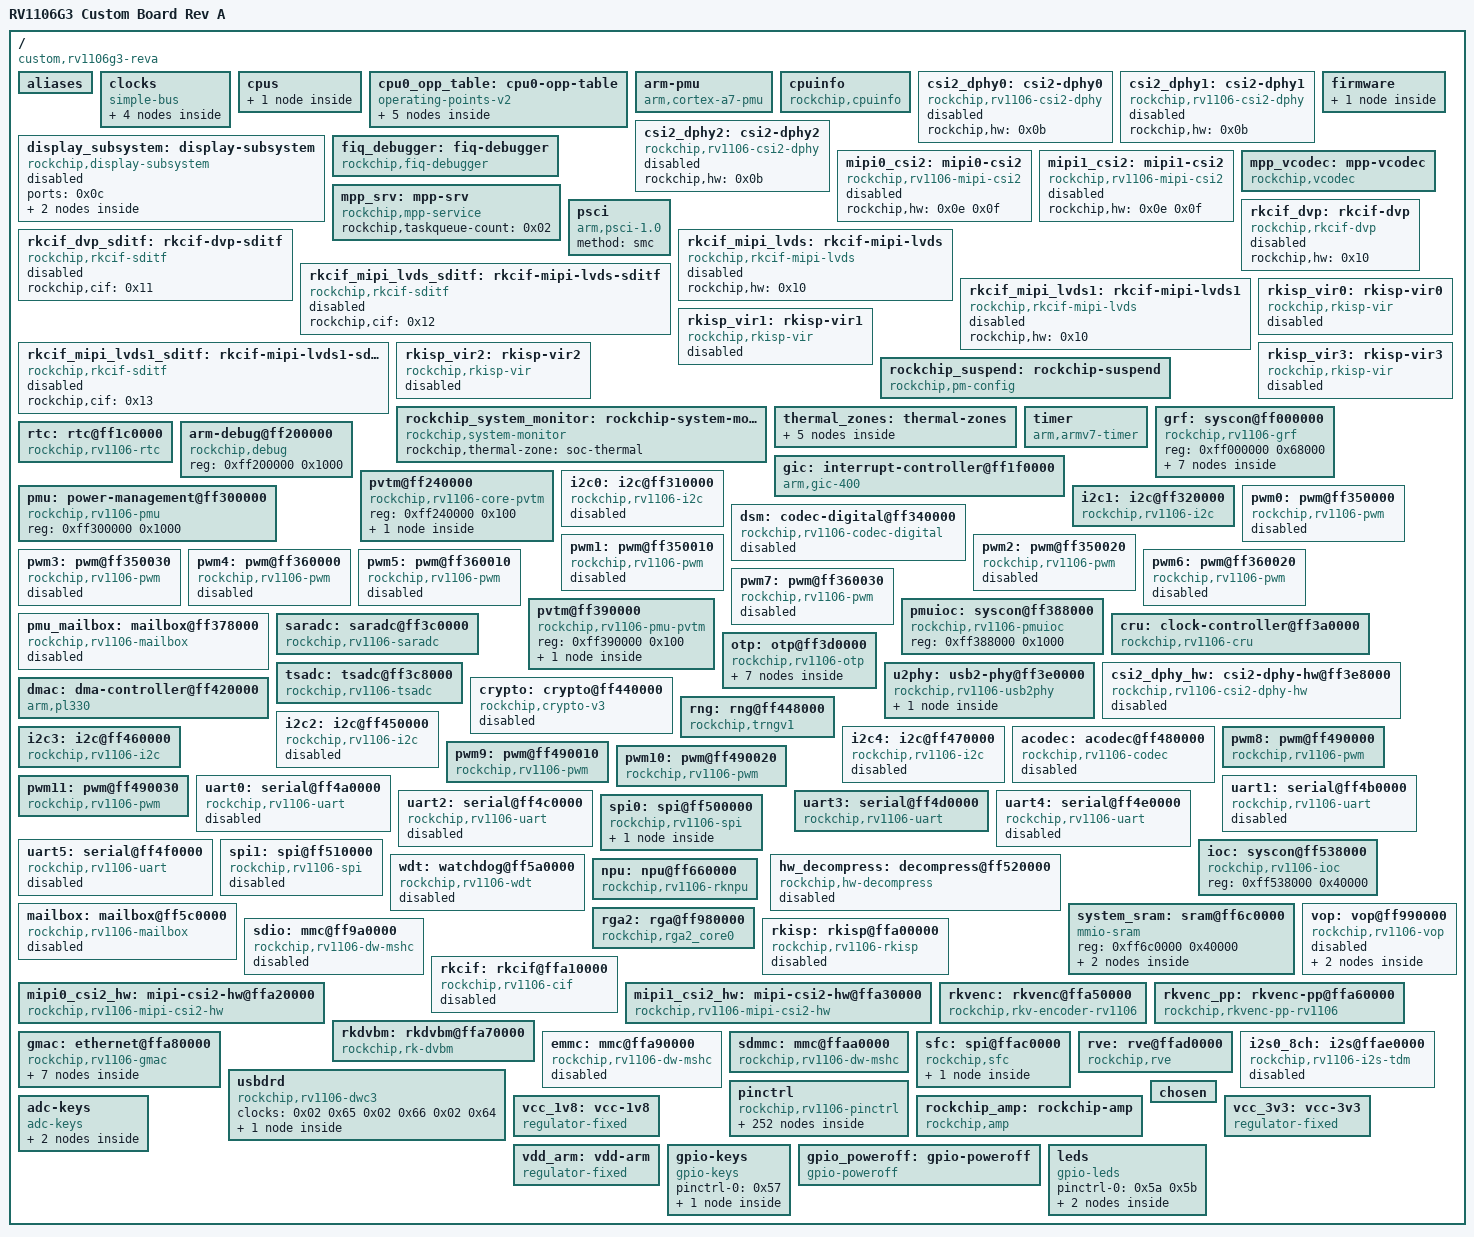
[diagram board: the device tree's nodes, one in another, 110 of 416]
/dts-v1/;

/ {
	#address-cells = <0x01>;
	#size-cells = <0x01>;
	compatible = "custom,rv1106g3-reva", "rockchip,rv1103g-38x38-ipc-v10", "rockchip,rv1106g3";
	interrupt-parent = <0x01>;
	model = "RV1106G3 Custom Board Rev A";

	aliases {
		csi2dphy0 = "/csi2-dphy0";
		csi2dphy1 = "/csi2-dphy1";
		csi2dphy2 = "/csi2-dphy2";
		ethernet0 = "/ethernet@ffa80000";
		gpio0 = "/pinctrl/gpio@ff380000";
		gpio1 = "/pinctrl/gpio@ff530000";
		gpio2 = "/pinctrl/gpio@ff540000";
		gpio3 = "/pinctrl/gpio@ff550000";
		gpio4 = "/pinctrl/gpio@ff560000";
		i2c0 = "/i2c@ff310000";
		i2c1 = "/i2c@ff320000";
		i2c2 = "/i2c@ff450000";
		i2c3 = "/i2c@ff460000";
		i2c4 = "/i2c@ff470000";
		mmc0 = "/mmc@ffa90000";
		mmc1 = "/mmc@ffaa0000";
		mmc2 = "/mmc@ff9a0000";
		pwm0 = "/pwm@ff350000";
		pwm1 = "/pwm@ff350010";
		pwm2 = "/pwm@ff350020";
		pwm3 = "/pwm@ff350030";
		pwm4 = "/pwm@ff360000";
		pwm5 = "/pwm@ff360010";
		pwm6 = "/pwm@ff360020";
		pwm7 = "/pwm@ff360030";
		pwm8 = "/pwm@ff490000";
		pwm9 = "/pwm@ff490010";
		pwm10 = "/pwm@ff490020";
		pwm11 = "/pwm@ff490030";
		rkcif_mipi_lvds0 = "/rkcif-mipi-lvds";
		rkcif_mipi_lvds1 = "/rkcif-mipi-lvds1";
		serial0 = "/serial@ff4a0000";
		serial1 = "/serial@ff4b0000";
		serial2 = "/serial@ff4c0000";
		serial3 = "/serial@ff4d0000";
		serial4 = "/serial@ff4e0000";
		serial5 = "/serial@ff4f0000";
		spi0 = "/spi@ff500000";
		spi1 = "/spi@ff510000";
		spi2 = "/spi@ffac0000";
	};

	clocks {
		compatible = "simple-bus";

		cpu_pvtpll: cpu-pvtpll {
			compatible = "fixed-clock";
			clock-frequency = "M|m";
			clock-output-names = "cpu_pvtpll";
			#clock-cells = <0x00>;
			status = "disabled";
			phandle = <0x5d>;
		};

		rkvenc_pvtpll: pvtpll-0 {
			compatible = "fixed-clock";
			clock-frequency = <0x18701a80>;
			clock-output-names = "clk_pvtpll_0";
			#clock-cells = <0x00>;
			phandle = <0x5e>;
		};

		npu_pvtpll: pvtpll-1 {
			compatible = "fixed-clock";
			clock-frequency = <0x1908b100>;
			clock-output-names = "clk_pvtpll_1";
			#clock-cells = <0x00>;
			phandle = <0x5f>;
		};

		xin24m: oscillator {
			compatible = "fixed-clock";
			clock-frequency = <0x16e3600>;
			clock-output-names = "xin24m";
			#clock-cells = <0x00>;
			phandle = <0x60>;
		};
	};

	cpus {
		#address-cells = <0x01>;
		#size-cells = <0x00>;

		cpu0: cpu@0 {
			device_type = "cpu";
			compatible = "arm,cortex-a7";
			reg = <0x00>;
			clocks = <0x02 0x05>;
			operating-points-v2 = <0x03>;
			cpu-supply = <0x04>;
			phandle = <0x07>;
		};
	};

	cpu0_opp_table: cpu0-opp-table {
		compatible = "operating-points-v2";
		opp-shared;
		nvmem-cells = <0x05>;
		nvmem-cell-names = "leakage";
		rockchip,pvtpll-avg-offset = <0x4001c>;
		rockchip,pvtpll-min-rate = <0x10d880>;
		rockchip,pvtpll-volt-step = <0x30d4>;
		rockchip,grf = <0x06>;
		rockchip,temp-hysteresis = <0x1388>;
		rockchip,low-temp = <0x2710>;
		rockchip,low-temp-min-volt = <0xdbba0>;
		phandle = <0x03>;

		opp-408000000 {
			opp-hz = <0x00 0x18519600>;
			opp-microvolt = <0xcf850 0xcf850 0xf4240>;
			clock-latency-ns = <0x9c40>;
		};

		opp-600000000 {
			opp-hz = <0x00 0x23c34600>;
			opp-microvolt = <0xcf850 0xcf850 0xf4240>;
			clock-latency-ns = <0x9c40>;
		};

		opp-816000000 {
			opp-hz = <0x00 0x30a32c00>;
			opp-microvolt = <0xcf850 0xcf850 0xf4240>;
			clock-latency-ns = <0x9c40>;
			opp-suspend;
		};

		opp-1104000000 {
			opp-hz = <0x00 0x41cdb400>;
			opp-microvolt = <0xcf850 0xcf850 0xf4240>;
			clock-latency-ns = <0x9c40>;
		};

		opp-1200000000 {
			opp-hz = <0x00 0x47868c00>;
			opp-microvolt = <0xcf850 0xcf850 0xf4240>;
			clock-latency-ns = <0x9c40>;
		};
	};

	arm-pmu {
		compatible = "arm,cortex-a7-pmu";
		interrupts = <0x00 0x7e 0x04>;
		interrupt-affinity = <0x07>;
	};

	cpuinfo {
		compatible = "rockchip,cpuinfo";
		nvmem-cells = <0x08 0x09 0x0a>;
		nvmem-cell-names = "id", "cpu-version", "cpu-code";
	};

	csi2_dphy0: csi2-dphy0 {
		compatible = "rockchip,rv1106-csi2-dphy";
		rockchip,hw = <0x0b>;
		status = "disabled";
		phandle = <0x61>;
	};

	csi2_dphy1: csi2-dphy1 {
		compatible = "rockchip,rv1106-csi2-dphy";
		rockchip,hw = <0x0b>;
		status = "disabled";
		phandle = <0x62>;
	};

	csi2_dphy2: csi2-dphy2 {
		compatible = "rockchip,rv1106-csi2-dphy";
		rockchip,hw = <0x0b>;
		status = "disabled";
		phandle = <0x63>;
	};

	display_subsystem: display-subsystem {
		compatible = "rockchip,display-subsystem";
		ports = <0x0c>;
		status = "disabled";
		phandle = <0x64>;

		route {

			route_rgb: route-rgb {
				status = "disabled";
				logo,uboot = "logo.bmp";
				logo,kernel = "logo_kernel.bmp";
				logo,mode = "center";
				charge_logo,mode = "center";
				connect = <0x0d>;
				phandle = <0x65>;
			};
		};
	};

	fiq_debugger: fiq-debugger {
		compatible = "rockchip,fiq-debugger";
		rockchip,serial-id = <0x02>;
		rockchip,wake-irq = <0x00>;
		rockchip,irq-mode-enable = <0x01>;
		rockchip,baudrate = <0x1c200>;
		interrupts = <0x00 0x7d 0x04>;
		status = "okay";
		phandle = <0x66>;
	};

	firmware {

		optee: optee {
			compatible = "linaro,optee-tz";
			method = "smc";
			status = "disabled";
			phandle = <0x67>;
		};
	};

	mipi0_csi2: mipi0-csi2 {
		compatible = "rockchip,rv1106-mipi-csi2";
		rockchip,hw = <0x0e 0x0f>;
		status = "disabled";
		phandle = <0x68>;
	};

	mipi1_csi2: mipi1-csi2 {
		compatible = "rockchip,rv1106-mipi-csi2";
		rockchip,hw = <0x0e 0x0f>;
		status = "disabled";
		phandle = <0x69>;
	};

	mpp_srv: mpp-srv {
		compatible = "rockchip,mpp-service";
		rockchip,taskqueue-count = <0x02>;
		status = "okay";
		phandle = <0x3d>;
	};

	mpp_vcodec: mpp-vcodec {
		compatible = "rockchip,vcodec";
		status = "okay";
		phandle = <0x6a>;
	};

	psci {
		compatible = "arm,psci-1.0";
		method = "smc";
	};

	rkcif_dvp: rkcif-dvp {
		compatible = "rockchip,rkcif-dvp";
		rockchip,hw = <0x10>;
		status = "disabled";
		phandle = <0x11>;
	};

	rkcif_dvp_sditf: rkcif-dvp-sditf {
		compatible = "rockchip,rkcif-sditf";
		rockchip,cif = <0x11>;
		status = "disabled";
		phandle = <0x6b>;
	};

	rkcif_mipi_lvds: rkcif-mipi-lvds {
		compatible = "rockchip,rkcif-mipi-lvds";
		rockchip,hw = <0x10>;
		status = "disabled";
		phandle = <0x12>;
	};

	rkcif_mipi_lvds_sditf: rkcif-mipi-lvds-sditf {
		compatible = "rockchip,rkcif-sditf";
		rockchip,cif = <0x12>;
		status = "disabled";
		phandle = <0x6c>;
	};

	rkcif_mipi_lvds1: rkcif-mipi-lvds1 {
		compatible = "rockchip,rkcif-mipi-lvds";
		rockchip,hw = <0x10>;
		status = "disabled";
		phandle = <0x13>;
	};

	rkcif_mipi_lvds1_sditf: rkcif-mipi-lvds1-sditf {
		compatible = "rockchip,rkcif-sditf";
		rockchip,cif = <0x13>;
		status = "disabled";
		phandle = <0x6d>;
	};

	rkisp_vir0: rkisp-vir0 {
		compatible = "rockchip,rkisp-vir";
		rockchip,hw = <0x14>;
		dvbm = <0x15>;
		status = "disabled";
		phandle = <0x6e>;
	};

	rkisp_vir1: rkisp-vir1 {
		compatible = "rockchip,rkisp-vir";
		rockchip,hw = <0x14>;
		dvbm = <0x15>;
		status = "disabled";
		phandle = <0x6f>;
	};

	rkisp_vir2: rkisp-vir2 {
		compatible = "rockchip,rkisp-vir";
		rockchip,hw = <0x14>;
		dvbm = <0x15>;
		status = "disabled";
		phandle = <0x70>;
	};

	rkisp_vir3: rkisp-vir3 {
		compatible = "rockchip,rkisp-vir";
		rockchip,hw = <0x14>;
		dvbm = <0x15>;
		status = "disabled";
		phandle = <0x71>;
	};

	rockchip_suspend: rockchip-suspend {
		compatible = "rockchip,pm-config";
		status = "okay";
		rockchip,sleep-io-config = <0x800 0x10800 0x20800 0x30400 0x40400 0x50000 0x60000>;
		phandle = <0x72>;
	};

	rockchip_system_monitor: rockchip-system-monitor {
		compatible = "rockchip,system-monitor";
		rockchip,thermal-zone = "soc-thermal";
		phandle = <0x73>;
	};

	thermal_zones: thermal-zones {
		phandle = <0x74>;

		soc_thermal: soc-thermal {
			polling-delay-passive = <0x14>;
			polling-delay = <0x3e8>;
			sustainable-power = <0x834>;
			thermal-sensors = <0x16 0x00>;
			phandle = <0x75>;

			trips {

				threshold: trip-point-0 {
					temperature = <0x124f8>;
					hysteresis = <0x7d0>;
					type = "passive";
					phandle = <0x76>;
				};

				target: trip-point-1 {
					temperature = <0x14c08>;
					hysteresis = <0x7d0>;
					type = "passive";
					phandle = <0x77>;
				};

				soc_crit: soc-crit {
					temperature = <0x1c138>;
					hysteresis = <0x7d0>;
					type = "critical";
					phandle = <0x78>;
				};
			};
		};
	};

	timer {
		compatible = "arm,armv7-timer";
		interrupts = <0x01 0x0d 0x104 0x01 0x0e 0x104>;
		clock-frequency = <0x16e3600>;
	};

	grf: syscon@ff000000 {
		compatible = "rockchip,rv1106-grf", "syscon", "simple-mfd";
		reg = <0xff000000 0x68000>;
		phandle = <0x06>;

		grf_cru: grf-clock-controller {
			compatible = "rockchip,rv1106-grf-cru";
			#clock-cells = <0x01>;
			phandle = <0x3b>;
		};

		reboot_mode: reboot-mode {
			compatible = "syscon-reboot-mode";
			offset = <0x20200>;
			mode-bootloader = <0x5242c301>;
			mode-charge = <0x5242c30b>;
			mode-fastboot = <0x5242c309>;
			mode-loader = <0x5242c301>;
			mode-normal = <0x5242c300>;
			mode-recovery = <0x5242c303>;
			mode-ums = <0x5242c30c>;
			mode-panic = <0x5242c307>;
			mode-watchdog = <0x5242c308>;
			phandle = <0x79>;
		};

		rgb: rgb {
			compatible = "rockchip,rv1106-rgb";
			status = "disabled";
			phandle = <0x7a>;

			ports {
				#address-cells = <0x01>;
				#size-cells = <0x00>;

				port@0 {
					reg = <0x00>;
					#address-cells = <0x01>;
					#size-cells = <0x00>;

					rgb_in_vop: endpoint@0 {
						reg = <0x00>;
						remote-endpoint = <0x0d>;
						phandle = <0x3a>;
					};
				};
			};
		};

		rknpor_powergood: rknpor-powergood {
			compatible = "rockchip,rv1106-npor-powergood";
			interrupts = <0x00 0x56 0x04>;
			status = "okay";
			phandle = <0x7b>;
		};
	};

	rtc: rtc@ff1c0000 {
		compatible = "rockchip,rv1106-rtc";
		reg = <0xff1c0000 0x1000>;
		rockchip,grf = <0x06>;
		interrupts = <0x00 0x62 0x04>;
		clocks = <0x02 0xef 0x02 0xee>;
		clock-names = "pclk_phy", "pclk_test";
		assigned-clocks = <0x02 0xef>;
		assigned-clock-rates = <0x16e3600>;
		status = "okay";
		phandle = <0x7c>;
	};

	gic: interrupt-controller@ff1f0000 {
		compatible = "arm,gic-400";
		interrupt-controller;
		#interrupt-cells = <0x03>;
		#address-cells = <0x00>;
		reg = <0xff1f1000 0x1000 0xff1f2000 0x2000 0xff1f4000 0x2000 0xff1f6000 0x2000>;
		interrupts = <0x01 0x09 0x104>;
		phandle = <0x01>;
	};

	arm-debug@ff200000 {
		compatible = "rockchip,debug";
		reg = <0xff200000 0x1000>;
	};

	pvtm@ff240000 {
		compatible = "rockchip,rv1106-core-pvtm";
		reg = <0xff240000 0x100>;
		#address-cells = <0x01>;
		#size-cells = <0x00>;

		pvtm@0 {
			reg = <0x00>;
			clocks = <0x02 0x40>;
			clock-names = "clk";
			resets = <0x02 0x6000e 0x02 0x6000f>;
			reset-names = "rst", "rst-p";
		};
	};

	pmu: power-management@ff300000 {
		compatible = "rockchip,rv1106-pmu", "syscon";
		reg = <0xff300000 0x1000>;
		phandle = <0x7d>;
	};

	i2c0: i2c@ff310000 {
		compatible = "rockchip,rv1106-i2c", "rockchip,rk3399-i2c";
		reg = <0xff310000 0x1000>;
		interrupts = <0x00 0x12 0x04>;
		#address-cells = <0x01>;
		#size-cells = <0x00>;
		clocks = <0x02 0x2a 0x02 0x29>;
		clock-names = "i2c", "pclk";
		pinctrl-names = "default";
		pinctrl-0 = <0x17>;
		status = "disabled";
		phandle = <0x7e>;
	};

	i2c1: i2c@ff320000 {
		compatible = "rockchip,rv1106-i2c", "rockchip,rk3399-i2c";
		reg = <0xff320000 0x1000>;
		interrupts = <0x00 0x13 0x04>;
		#address-cells = <0x01>;
		#size-cells = <0x00>;
		clocks = <0x02 0x78 0x02 0x77>;
		clock-names = "i2c", "pclk";
		pinctrl-names = "default";
		pinctrl-0 = <0x18>;
		status = "okay";
		clock-frequency = <0x186a0>;
		phandle = <0x7f>;
	};

	dsm: codec-digital@ff340000 {
		compatible = "rockchip,rv1106-codec-digital", "rockchip,codec-digital-v1";
		reg = <0xff340000 0x1000>;
		clocks = <0x02 0x24 0x02 0x23>;
		clock-names = "dac", "pclk";
		resets = <0x02 0x48061>;
		reset-names = "reset";
		rockchip,grf = <0x06>;
		rockchip,pwm-output-mode;
		#sound-dai-cells = <0x00>;
		pinctrl-names = "default";
		pinctrl-0 = <0x19>;
		status = "disabled";
		phandle = <0x80>;
	};

	pwm0: pwm@ff350000 {
		compatible = "rockchip,rv1106-pwm", "rockchip,rk3328-pwm";
		reg = <0xff350000 0x10>;
		interrupts = <0x00 0x1f 0x04>;
		#pwm-cells = <0x03>;
		pinctrl-names = "active";
		pinctrl-0 = <0x1a>;
		clocks = <0x02 0x36 0x02 0x35>;
		clock-names = "pwm", "pclk";
		status = "disabled";
		phandle = <0x81>;
	};

	pwm1: pwm@ff350010 {
		compatible = "rockchip,rv1106-pwm", "rockchip,rk3328-pwm";
		reg = <0xff350010 0x10>;
		interrupts = <0x00 0x1f 0x04>;
		#pwm-cells = <0x03>;
		pinctrl-names = "active";
		pinctrl-0 = <0x1b>;
		clocks = <0x02 0x36 0x02 0x35>;
		clock-names = "pwm", "pclk";
		status = "disabled";
		phandle = <0x82>;
	};

	pwm2: pwm@ff350020 {
		compatible = "rockchip,rv1106-pwm", "rockchip,rk3328-pwm";
		reg = <0xff350020 0x10>;
		interrupts = <0x00 0x1f 0x04>;
		#pwm-cells = <0x03>;
		pinctrl-names = "active";
		pinctrl-0 = <0x1c>;
		clocks = <0x02 0x36 0x02 0x35>;
		clock-names = "pwm", "pclk";
		status = "disabled";
		phandle = <0x83>;
	};

	pwm3: pwm@ff350030 {
		compatible = "rockchip,rv1106-pwm", "rockchip,rk3328-pwm";
		reg = <0xff350030 0x10>;
		interrupts = <0x00 0x1f 0x04 0x00 0x20 0x04>;
		#pwm-cells = <0x03>;
		pinctrl-names = "active";
		pinctrl-0 = <0x1d>;
		clocks = <0x02 0x36 0x02 0x35>;
		clock-names = "pwm", "pclk";
		status = "disabled";
		phandle = <0x84>;
	};

	pwm4: pwm@ff360000 {
		compatible = "rockchip,rv1106-pwm", "rockchip,rk3328-pwm";
		reg = <0xff360000 0x10>;
		interrupts = <0x00 0x21 0x04>;
		#pwm-cells = <0x03>;
		pinctrl-names = "active";
		pinctrl-0 = <0x1e>;
		clocks = <0x02 0x44 0x02 0x43>;
		clock-names = "pwm", "pclk";
		status = "disabled";
		phandle = <0x85>;
	};

	pwm5: pwm@ff360010 {
		compatible = "rockchip,rv1106-pwm", "rockchip,rk3328-pwm";
		reg = <0xff360010 0x10>;
		interrupts = <0x00 0x21 0x04>;
		#pwm-cells = <0x03>;
		pinctrl-names = "active";
		pinctrl-0 = <0x1f>;
		clocks = <0x02 0x44 0x02 0x43>;
		clock-names = "pwm", "pclk";
		status = "disabled";
		phandle = <0x86>;
	};

	pwm6: pwm@ff360020 {
		compatible = "rockchip,rv1106-pwm", "rockchip,rk3328-pwm";
		reg = <0xff360020 0x10>;
		interrupts = <0x00 0x21 0x04>;
		#pwm-cells = <0x03>;
		pinctrl-names = "active";
		pinctrl-0 = <0x20>;
		clocks = <0x02 0x44 0x02 0x43>;
		clock-names = "pwm", "pclk";
		status = "disabled";
		phandle = <0x87>;
	};

	pwm7: pwm@ff360030 {
		compatible = "rockchip,rv1106-pwm", "rockchip,rk3328-pwm";
		reg = <0xff360030 0x10>;
		interrupts = <0x00 0x21 0x04 0x00 0x22 0x04>;
		#pwm-cells = <0x03>;
		pinctrl-names = "active";
		pinctrl-0 = <0x21>;
		clocks = <0x02 0x44 0x02 0x43>;
		clock-names = "pwm", "pclk";
		status = "disabled";
		phandle = <0x88>;
	};

	pmu_mailbox: mailbox@ff378000 {
		compatible = "rockchip,rv1106-mailbox", "rockchip,rk3368-mailbox";
		reg = <0xff378000 0x200>;
		interrupts = <0x00 0x72 0x04>;
		clocks = <0x02 0x7a>;
		clock-names = "pclk_mailbox";
		#mbox-cells = <0x01>;
		status = "disabled";
		phandle = <0x89>;
	};

	pmuioc: syscon@ff388000 {
		compatible = "rockchip,rv1106-pmuioc", "syscon";
		reg = <0xff388000 0x1000>;
		phandle = <0x4b>;
	};

	pvtm@ff390000 {
		compatible = "rockchip,rv1106-pmu-pvtm";
		reg = <0xff390000 0x100>;
		#address-cells = <0x01>;
		#size-cells = <0x00>;

		pvtm@0 {
			reg = <0x01>;
			clocks = <0x02 0x7e 0x02 0x7f>;
			clock-names = "clk", "pclk";
			resets = <0x02 0x14 0x02 0x15>;
			reset-names = "rst", "rst-p";
		};
	};

	cru: clock-controller@ff3a0000 {
		compatible = "rockchip,rv1106-cru";
		reg = <0xff3a0000 0x20000>;
		rockchip,grf = <0x06>;
		#clock-cells = <0x01>;
		#reset-cells = <0x01>;
		assigned-clocks = <0x02 0x04 0x02 0x03 0x02 0x05 0x02 0x39 0x02 0x3a 0x02 0x38 0x02 0x3c 0x02 0xcb 0x02 0x82 0x02 0x83>;
		assigned-clock-rates = <0x46cf7100 0x3b9aca00 0x41cdb400 0x17d78400 0xbebc200 0x5f5e100 0x11e1a300 0x5f5e100 0x5f5e100 0xbebc200>;
		phandle = <0x02>;
	};

	saradc: saradc@ff3c0000 {
		compatible = "rockchip,rv1106-saradc";
		reg = <0xff3c0000 0x200>;
		interrupts = <0x00 0x3e 0x04>;
		#io-channel-cells = <0x01>;
		clocks = <0x02 0x4d 0x02 0x4c>;
		clock-names = "saradc", "apb_pclk";
		resets = <0x02 0x48033>;
		reset-names = "saradc-apb";
		status = "okay";
		vref-supply = <0x22>;
		phandle = <0x56>;
	};

	tsadc: tsadc@ff3c8000 {
		compatible = "rockchip,rv1106-tsadc";
		reg = <0xff3c8000 0x1000>;
		rockchip,grf = <0x06>;
		interrupts = <0x00 0x61 0x04>;
		clocks = <0x02 0x113 0x02 0x112 0x02 0x114>;
		clock-names = "tsadc", "apb_pclk", "tsen";
		assigned-clocks = <0x02 0x113 0x02 0x114>;
		assigned-clock-rates = <0xf4240 0xb71b00>;
		resets = <0x02 0x70021 0x02 0x70020>;
		reset-names = "tsadc", "tsadc-apb";
		#thermal-sensor-cells = <0x01>;
		rockchip,hw-tshut-temp = <0x1d4c0>;
		rockchip,hw-tshut-mode = <0x00>;
		rockchip,hw-tshut-polarity = <0x00>;
		status = "okay";
		phandle = <0x16>;
	};

	otp: otp@ff3d0000 {
		compatible = "rockchip,rv1106-otp";
		reg = <0xff3d0000 0x4000>;
		#address-cells = <0x01>;
		#size-cells = <0x01>;
		clocks = <0x02 0x107 0x02 0x106 0x02 0x105 0x02 0x10b 0x02 0x104 0x02 0x10c>;
		clock-names = "usr", "sbpi", "apb", "phy", "arb", "pmc";
		resets = <0x02 0x70026 0x02 0x70025 0x02 0x70023 0x02 0x7002e 0x02 0x7002b 0x02 0x7002f>;
		reset-names = "usr", "sbpi", "apb", "phy", "arb", "pmc";
		phandle = <0x8a>;

		cpu_code: cpu-code@2 {
			reg = <0x02 0x02>;
			phandle = <0x0a>;
		};

		otp_cpu_version: cpu-version@8 {
			reg = <0x08 0x01>;
			bits = <0x03 0x03>;
			phandle = <0x09>;
		};

		otp_id: id@a {
			reg = <0x0a 0x10>;
			phandle = <0x08>;
		};

		cpu_leakage: cpu-leakage@1a {
			reg = <0x1a 0x01>;
			phandle = <0x05>;
		};

		log_leakage: log-leakage@1b {
			reg = <0x1b 0x01>;
			phandle = <0x8b>;
		};

		macphy_bgs: macphy-bgs@2d {
			reg = <0x2d 0x01>;
			phandle = <0x42>;
		};

		macphy_txlevel: macphy-txlevel@2e {
			reg = <0x2e 0x02>;
			phandle = <0x43>;
		};
	};

	u2phy: usb2-phy@ff3e0000 {
		compatible = "rockchip,rv1106-usb2phy";
		reg = <0xff3e0000 0x8000>;
		rockchip,usbgrf = <0x06>;
		clocks = <0x02 0x68 0x02 0x67>;
		clock-names = "phyclk", "pclk";
		resets = <0x02 0x48052 0x02 0x48051>;
		reset-names = "u2phy", "u2phy-apb";
		#clock-cells = <0x00>;
		status = "okay";
		phandle = <0x49>;

		u2phy_otg: otg-port {
			#phy-cells = <0x00>;
			interrupts = <0x00 0x3a 0x04 0x00 0x3b 0x04 0x00 0x3c 0x04 0x00 0x3d 0x04>;
			interrupt-names = "otg-bvalid", "otg-id", "linestate", "disconnect";
			status = "okay";
			rockchip,dis-u2-susphy;
			phandle = <0x48>;
		};
	};

	csi2_dphy_hw: csi2-dphy-hw@ff3e8000 {
		compatible = "rockchip,rv1106-csi2-dphy-hw";
		reg = <0xff3e8000 0x8000>;
		clocks = <0x02 0xe6>;
		clock-names = "pclk";
		resets = <0x02 0x5001e>;
		reset-names = "srst_p_csiphy";
		rockchip,grf = <0x06>;
		status = "disabled";
		phandle = <0x0b>;
	};

	dmac: dma-controller@ff420000 {
		compatible = "arm,pl330", "arm,primecell";
		reg = <0xff420000 0x4000>;
		interrupts = <0x00 0x3f 0x04 0x00 0x40 0x04 0x00 0x41 0x04 0x00 0x42 0x04 0x00 0x43 0x04 0x00 0x44 0x04 0x00 0x45 0x04 0x00 0x46 0x04 0x00 0x4f 0x04>;
		#dma-cells = <0x01>;
		clocks = <0x02 0x22>;
		clock-names = "apb_pclk";
		arm,pl330-periph-burst;
		phandle = <0x2a>;
	};

	crypto: crypto@ff440000 {
		compatible = "rockchip,crypto-v3";
		reg = <0xff440000 0x2000>;
		interrupts = <0x00 0x0f 0x04>;
		clocks = <0x02 0x1d 0x02 0x1e 0x02 0x1b 0x02 0x1c>;
		clock-names = "aclk", "hclk", "sclk", "pka";
		assigned-clocks = <0x02 0x1b 0x02 0x1c>;
		assigned-clock-rates = <0xbebc200 0xbebc200>;
		resets = <0x02 0x4803b>;
		reset-names = "crypto-rst";
		status = "disabled";
		phandle = <0x8c>;
	};

	rng: rng@ff448000 {
		compatible = "rockchip,trngv1";
		reg = <0xff448000 0x200>;
		interrupts = <0x00 0x11 0x04>;
		clocks = <0x02 0x5a>;
		clock-names = "hclk_trng";
		resets = <0x02 0x48039>;
		reset-names = "reset";
		status = "okay";
		phandle = <0x8d>;
	};

	i2c2: i2c@ff450000 {
		compatible = "rockchip,rv1106-i2c", "rockchip,rk3399-i2c";
		reg = <0xff450000 0x1000>;
		interrupts = <0x00 0x14 0x04>;
		#address-cells = <0x01>;
		#size-cells = <0x00>;
		clocks = <0x02 0x2c 0x02 0x2b>;
		clock-names = "i2c", "pclk";
		pinctrl-names = "default";
		pinctrl-0 = <0x23>;
		status = "disabled";
		phandle = <0x8e>;
	};

	i2c3: i2c@ff460000 {
		compatible = "rockchip,rv1106-i2c", "rockchip,rk3399-i2c";
		reg = <0xff460000 0x1000>;
		interrupts = <0x00 0x15 0x04>;
		#address-cells = <0x01>;
		#size-cells = <0x00>;
		clocks = <0x02 0x2e 0x02 0x2d>;
		clock-names = "i2c", "pclk";
		pinctrl-names = "default";
		pinctrl-0 = <0x24>;
		status = "okay";
		clock-frequency = <0x186a0>;
		phandle = <0x8f>;
	};

	i2c4: i2c@ff470000 {
		compatible = "rockchip,rv1106-i2c", "rockchip,rk3399-i2c";
		reg = <0xff470000 0x1000>;
		interrupts = <0x00 0x16 0x04>;
		#address-cells = <0x01>;
		#size-cells = <0x00>;
		clocks = <0x02 0x30 0x02 0x2f>;
		clock-names = "i2c", "pclk";
		pinctrl-names = "default";
		pinctrl-0 = <0x25>;
		status = "disabled";
		phandle = <0x90>;
	};

	acodec: acodec@ff480000 {
		compatible = "rockchip,rv1106-codec";
		reg = <0xff480000 0x1000>;
		rockchip,grf = <0x06>;
		clocks = <0x02 0x18 0x02 0x19 0x02 0x9f>;
		clock-names = "pclk_acodec", "mclk_acodec", "mclk_cpu";
		resets = <0x02 0x48063>;
		reset-names = "acodec-reset";
		acodec,micbias;
		init-mic-gain = <0x22>;
		status = "disabled";
		phandle = <0x91>;
	};

	pwm8: pwm@ff490000 {
		compatible = "rockchip,rv1106-pwm", "rockchip,rk3328-pwm";
		reg = <0xff490000 0x10>;
		interrupts = <0x00 0x23 0x04>;
		#pwm-cells = <0x03>;
		pinctrl-names = "active";
		pinctrl-0 = <0x26>;
		clocks = <0x02 0x47 0x02 0x46>;
		clock-names = "pwm", "pclk";
		status = "okay";
		phandle = <0x92>;
	};

	pwm9: pwm@ff490010 {
		compatible = "rockchip,rv1106-pwm", "rockchip,rk3328-pwm";
		reg = <0xff490010 0x10>;
		interrupts = <0x00 0x23 0x04>;
		#pwm-cells = <0x03>;
		pinctrl-names = "active";
		pinctrl-0 = <0x27>;
		clocks = <0x02 0x47 0x02 0x46>;
		clock-names = "pwm", "pclk";
		status = "okay";
		phandle = <0x93>;
	};

	pwm10: pwm@ff490020 {
		compatible = "rockchip,rv1106-pwm", "rockchip,rk3328-pwm";
		reg = <0xff490020 0x10>;
		interrupts = <0x00 0x23 0x04>;
		#pwm-cells = <0x03>;
		pinctrl-names = "active";
		pinctrl-0 = <0x28>;
		clocks = <0x02 0x47 0x02 0x46>;
		clock-names = "pwm", "pclk";
		status = "okay";
		phandle = <0x94>;
	};

	pwm11: pwm@ff490030 {
		compatible = "rockchip,rv1106-pwm", "rockchip,rk3328-pwm";
		reg = <0xff490030 0x10>;
		interrupts = <0x00 0x23 0x04 0x00 0x24 0x04>;
		#pwm-cells = <0x03>;
		pinctrl-names = "active";
		pinctrl-0 = <0x29>;
		clocks = <0x02 0x47 0x02 0x46>;
		clock-names = "pwm", "pclk";
		status = "okay";
		phandle = <0x95>;
	};

	uart0: serial@ff4a0000 {
		compatible = "rockchip,rv1106-uart", "snps,dw-apb-uart";
		reg = <0xff4a0000 0x100>;
		interrupts = <0x00 0x19 0x04>;
		reg-shift = <0x02>;
		reg-io-width = <0x04>;
		dmas = <0x2a 0x07 0x2a 0x06>;
		clock-frequency = <0x16e3600>;
		clocks = <0x02 0xac 0x02 0x3f>;
		clock-names = "baudclk", "apb_pclk";
		pinctrl-names = "default";
		pinctrl-0 = <0x2b>;
		status = "disabled";
		phandle = <0x96>;
	};

	uart1: serial@ff4b0000 {
		compatible = "rockchip,rv1106-uart", "snps,dw-apb-uart";
		reg = <0xff4b0000 0x100>;
		interrupts = <0x00 0x1a 0x04>;
		reg-shift = <0x02>;
		reg-io-width = <0x04>;
		dmas = <0x2a 0x09 0x2a 0x08>;
		clock-frequency = <0x16e3600>;
		clocks = <0x02 0xb0 0x02 0x41>;
		clock-names = "baudclk", "apb_pclk";
		pinctrl-names = "default";
		pinctrl-0 = <0x2c 0x2d 0x2e>;
		status = "disabled";
		phandle = <0x97>;
	};

	uart2: serial@ff4c0000 {
		compatible = "rockchip,rv1106-uart", "snps,dw-apb-uart";
		reg = <0xff4c0000 0x100>;
		interrupts = <0x00 0x1b 0x04>;
		reg-shift = <0x02>;
		reg-io-width = <0x04>;
		dmas = <0x2a 0x0b 0x2a 0x0a>;
		clock-frequency = <0x16e3600>;
		clocks = <0x02 0xb4 0x02 0x5c>;
		clock-names = "baudclk", "apb_pclk";
		pinctrl-names = "default";
		pinctrl-0 = <0x2f>;
		status = "disabled";
		phandle = <0x98>;
	};

	uart3: serial@ff4d0000 {
		compatible = "rockchip,rv1106-uart", "snps,dw-apb-uart";
		reg = <0xff4d0000 0x100>;
		interrupts = <0x00 0x1c 0x04>;
		reg-shift = <0x02>;
		reg-io-width = <0x04>;
		dmas = <0x2a 0x0d 0x2a 0x0c>;
		clock-frequency = <0x16e3600>;
		clocks = <0x02 0xb8 0x02 0x5e>;
		clock-names = "baudclk", "apb_pclk";
		pinctrl-names = "default";
		pinctrl-0 = <0x30>;
		status = "okay";
		phandle = <0x99>;
	};

	uart4: serial@ff4e0000 {
		compatible = "rockchip,rv1106-uart", "snps,dw-apb-uart";
		reg = <0xff4e0000 0x100>;
		interrupts = <0x00 0x1d 0x04>;
		reg-shift = <0x02>;
		reg-io-width = <0x04>;
		dmas = <0x2a 0x0f 0x2a 0x0e>;
		clock-frequency = <0x16e3600>;
		clocks = <0x02 0xbc 0x02 0x60>;
		clock-names = "baudclk", "apb_pclk";
		pinctrl-names = "default";
		pinctrl-0 = <0x31>;
		status = "disabled";
		phandle = <0x9a>;
	};

	uart5: serial@ff4f0000 {
		compatible = "rockchip,rv1106-uart", "snps,dw-apb-uart";
		reg = <0xff4f0000 0x100>;
		interrupts = <0x00 0x1e 0x04>;
		reg-shift = <0x02>;
		reg-io-width = <0x04>;
		dmas = <0x2a 0x11 0x2a 0x10>;
		clock-frequency = <0x16e3600>;
		clocks = <0x02 0xc0 0x02 0x62>;
		clock-names = "baudclk", "apb_pclk";
		pinctrl-names = "default";
		pinctrl-0 = <0x32 0x33 0x34>;
		status = "disabled";
		phandle = <0x9b>;
	};

	spi0: spi@ff500000 {
		compatible = "rockchip,rv1106-spi", "rockchip,rk3066-spi";
		reg = <0xff500000 0x1000>;
		interrupts = <0x00 0x17 0x04>;
		#address-cells = <0x01>;
		#size-cells = <0x00>;
		clocks = <0x02 0xcd 0x02 0xcc 0x02 0xce>;
		clock-names = "spiclk", "apb_pclk", "sclk_in";
		dmas = <0x2a 0x01 0x2a 0x00>;
		dma-names = "tx", "rx";
		pinctrl-names = "default";
		pinctrl-0 = <0x35 0x36>;
		status = "okay";
		phandle = <0x9c>;

		spidev@0 {
			compatible = "rockchip,spidev";
			reg = <0x00>;
			spi-max-frequency = <0x2faf080>;
		};
	};

	spi1: spi@ff510000 {
		compatible = "rockchip,rv1106-spi", "rockchip,rk3066-spi";
		reg = <0xff510000 0x1000>;
		interrupts = <0x00 0x18 0x04>;
		#address-cells = <0x01>;
		#size-cells = <0x00>;
		clocks = <0x02 0x4f 0x02 0x4e>;
		clock-names = "spiclk", "apb_pclk";
		assigned-clocks = <0x02 0x4f>;
		assigned-clock-rates = <0xbebc200>;
		dmas = <0x2a 0x03 0x2a 0x02>;
		dma-names = "tx", "rx";
		pinctrl-names = "default";
		pinctrl-0 = <0x37 0x38 0x39>;
		status = "disabled";
		phandle = <0x9d>;
	};

	hw_decompress: decompress@ff520000 {
		compatible = "rockchip,hw-decompress";
		reg = <0xff520000 0x1000>;
		interrupts = <0x00 0x70 0x04>;
		clocks = <0x02 0x1f 0x02 0x21 0x02 0x20>;
		clock-names = "aclk", "dclk", "pclk";
		resets = <0x02 0x4805b>;
		reset-names = "dresetn";
		status = "disabled";
		phandle = <0x9e>;
	};

	ioc: syscon@ff538000 {
		compatible = "rockchip,rv1106-ioc", "syscon";
		reg = <0xff538000 0x40000>;
		phandle = <0x4a>;
	};

	wdt: watchdog@ff5a0000 {
		compatible = "rockchip,rv1106-wdt", "snps,dw-wdt";
		reg = <0xff5a0000 0x100>;
		clocks = <0x02 0x6a 0x02 0x69>;
		clock-names = "tclk", "pclk";
		interrupts = <0x00 0x2e 0x04>;
		status = "disabled";
		phandle = <0x9f>;
	};

	mailbox: mailbox@ff5c0000 {
		compatible = "rockchip,rv1106-mailbox", "rockchip,rk3368-mailbox";
		reg = <0xff5c0000 0x200>;
		interrupts = <0x00 0x01 0x04>;
		clocks = <0x02 0x123>;
		clock-names = "pclk_mailbox";
		#mbox-cells = <0x01>;
		status = "disabled";
		phandle = <0xa0>;
	};

	npu: npu@ff660000 {
		compatible = "rockchip,rv1106-rknpu";
		reg = <0xff660000 0x10000>;
		interrupts = <0x00 0x6d 0x04>;
		clocks = <0x02 0x17 0x02 0x16>;
		clock-names = "aclk", "hclk";
		assigned-clocks = <0x02 0x17>;
		assigned-clock-rates = <0x1908b100>;
		resets = <0x02 0x5800a 0x02 0x58009>;
		reset-names = "srst_a", "srst_h";
		status = "okay";
		phandle = <0xa1>;
	};

	system_sram: sram@ff6c0000 {
		compatible = "mmio-sram";
		reg = <0xff6c0000 0x40000>;
		#address-cells = <0x01>;
		#size-cells = <0x01>;
		ranges = <0x00 0xff6c0000 0x40000>;
		phandle = <0xa2>;

		rkisp_sram: rkisp-sram@0 {
			reg = <0x00 0x3e000>;
			phandle = <0x3c>;
		};

		hpmcu_sram: hpmcu-sram@3e000 {
			reg = <0x3e000 0x2000>;
			phandle = <0xa3>;
		};
	};

	rga2: rga@ff980000 {
		compatible = "rockchip,rga2_core0";
		reg = <0xff980000 0x1000>;
		interrupts = <0x00 0x57 0x04>;
		clocks = <0x02 0x10e 0x02 0x10d 0x02 0x10f>;
		clock-names = "aclk_rga2", "hclk_rga2", "clk_rga2";
		status = "okay";
		phandle = <0xa4>;
	};

	vop: vop@ff990000 {
		compatible = "rockchip,rv1106-vop";
		reg = <0xff990000 0x200>;
		reg-names = "regs";
		rockchip,grf = <0x06>;
		interrupts = <0x00 0x59 0x04>;
		clocks = <0x02 0x11b 0x02 0x11a 0x02 0x119>;
		clock-names = "aclk_vop", "dclk_vop", "hclk_vop";
		status = "disabled";
		phandle = <0xa5>;

		vop_out: port {
			#address-cells = <0x01>;
			#size-cells = <0x00>;
			phandle = <0x0c>;

			vop_out_rgb: endpoint@0 {
				reg = <0x00>;
				remote-endpoint = <0x3a>;
				phandle = <0x0d>;
			};
		};
	};

	sdio: mmc@ff9a0000 {
		compatible = "rockchip,rv1106-dw-mshc", "rockchip,rk3288-dw-mshc";
		reg = <0xff9a0000 0x4000>;
		interrupts = <0x00 0x31 0x04>;
		clocks = <0x02 0x111 0x02 0x110 0x3b 0x05 0x3b 0x06>;
		clock-names = "biu", "ciu", "ciu-drive", "ciu-sample";
		fifo-depth = <0x100>;
		max-frequency = <0xbebc200>;
		status = "disabled";
		phandle = <0xa6>;
	};

	rkisp: rkisp@ffa00000 {
		compatible = "rockchip,rv1106-rkisp";
		reg = <0xffa00000 0x7f00>;
		interrupts = <0x00 0x69 0x04 0x00 0x68 0x04 0x00 0x67 0x04>;
		interrupt-names = "isp_irq", "mi_irq", "mipi_irq";
		clocks = <0x02 0xe4 0x02 0xe3 0x02 0xe5 0x02 0xf8>;
		clock-names = "aclk_isp", "hclk_isp", "clk_isp_core", "clk_isp_core_vicap";
		rockchip,sram = <0x3c>;
		status = "disabled";
		phandle = <0x14>;
	};

	rkcif: rkcif@ffa10000 {
		compatible = "rockchip,rv1106-cif";
		reg = <0xffa10000 0x10000>;
		reg-names = "cif_regs";
		interrupts = <0x00 0x6a 0x04>;
		interrupt-names = "cif-intr";
		clocks = <0x02 0xf2 0x02 0xf3 0x02 0xf0 0x02 0xf1 0x02 0xf4 0x02 0xf5 0x02 0xf6 0x02 0xf7 0x02 0xf8 0x02 0xc4 0x02 0xc8 0x02 0xdc>;
		clock-names = "aclk_cif", "hclk_cif", "dclk_cif", "pclk_cif", "i0clk_cif", "i1clk_cif", "rx0clk_cif", "rx1clk_cif", "isp0clk_cif", "sclk_m0_cif", "sclk_m1_cif", "pclk_vepu_cif";
		resets = <0x02 0x5000c 0x02 0x5000d 0x02 0x5000a 0x02 0x5000b 0x02 0x5000e 0x02 0x5000f 0x02 0x50010 0x02 0x50011 0x02 0x50012 0x02 0x6800e>;
		reset-names = "rst_cif_a", "rst_cif_h", "rst_cif_d", "rst_cif_p", "rst_cif_i0", "rst_cif_i1", "rst_cif_rx0", "rst_cif_rx1", "rst_cif_isp0", "rst_cif_pclk_vepu";
		rockchip,grf = <0x06>;
		status = "disabled";
		phandle = <0x10>;
	};

	mipi0_csi2_hw: mipi-csi2-hw@ffa20000 {
		compatible = "rockchip,rv1106-mipi-csi2-hw";
		reg = <0xffa20000 0x10000>;
		reg-names = "csihost_regs";
		interrupts = <0x00 0x63 0x04 0x00 0x64 0x04>;
		interrupt-names = "csi-intr1", "csi-intr2";
		clocks = <0x02 0xdd 0x02 0xde>;
		clock-names = "pclk_csi2host", "clk_rxbyte_hs";
		resets = <0x02 0x50014>;
		reset-names = "srst_csihost_p";
		status = "okay";
		phandle = <0x0e>;
	};

	mipi1_csi2_hw: mipi-csi2-hw@ffa30000 {
		compatible = "rockchip,rv1106-mipi-csi2-hw";
		reg = <0xffa30000 0x10000>;
		reg-names = "csihost_regs";
		interrupts = <0x00 0x65 0x04 0x00 0x66 0x04>;
		interrupt-names = "csi-intr1", "csi-intr2";
		clocks = <0x02 0xdf 0x02 0xe0>;
		clock-names = "pclk_csi2host", "clk_rxbyte_hs";
		resets = <0x02 0x50016>;
		reset-names = "srst_csihost_p";
		status = "okay";
		phandle = <0x0f>;
	};

	rkvenc: rkvenc@ffa50000 {
		compatible = "rockchip,rkv-encoder-rv1106";
		reg = <0xffa50000 0x6000>;
		interrupts = <0x00 0x6b 0x04>;
		interrupt-names = "irq_rkvenc";
		clocks = <0x02 0xd1 0x02 0xd0 0x02 0xd2>;
		clock-names = "aclk_vcodec", "hclk_vcodec", "clk_core";
		rockchip,normal-rates = <0x11e1a300 0x00 0x18701a80>;
		assigned-clocks = <0x02 0xd1 0x02 0xd2>;
		assigned-clock-rates = <0x11e1a300 0x17d78400>;
		resets = <0x02 0x68009 0x02 0x68008 0x02 0x6800a>;
		reset-names = "video_a", "video_h", "video_core";
		rockchip,srv = <0x3d>;
		rockchip,taskqueue-node = <0x00>;
		dvbm = <0x15>;
		status = "okay";
		phandle = <0xa7>;
	};

	rkvenc_pp: rkvenc-pp@ffa60000 {
		compatible = "rockchip,rkvenc-pp-rv1106";
		reg = <0xffa60000 0x900>;
		interrupts = <0x00 0x6c 0x04>;
		interrupt-names = "irq_rkvenc_pp";
		clocks = <0x02 0xd7 0x02 0xd6>;
		clock-names = "aclk_vepu_pp", "hclk_vepu_pp";
		assigned-clocks = <0x02 0xd7 0x02 0xd6>;
		resets = <0x02 0x6800c 0x02 0x6800b>;
		rockchip,srv = <0x3d>;
		rockchip,taskqueue-node = <0x01>;
		status = "okay";
		phandle = <0xa8>;
	};

	rkdvbm: rkdvbm@ffa70000 {
		compatible = "rockchip,rk-dvbm";
		reg = <0xffa70000 0x90>;
		interrupts = <0x00 0x74 0x04>;
		interrupt-names = "irq_rkdvbm";
		clocks = <0x02 0xd3>;
		clock-names = "clk_core";
		assigned-clocks = <0x02 0xd3>;
		assigned-clock-rates = <0xbebc200>;
		resets = <0x02 0x6800d>;
		reset-names = "dvbm_rst";
		status = "okay";
		phandle = <0x15>;
	};

	gmac: ethernet@ffa80000 {
		compatible = "rockchip,rv1106-gmac", "snps,dwmac-4.20a";
		reg = <0xffa80000 0x10000>;
		interrupts = <0x00 0x5d 0x04 0x00 0x60 0x04>;
		interrupt-names = "macirq", "eth_wake_irq";
		rockchip,grf = <0x06>;
		clocks = <0x02 0xfe 0x02 0xff 0x02 0xfb 0x02 0xfc>;
		clock-names = "stmmaceth", "clk_mac_ref", "aclk_mac", "pclk_mac";
		resets = <0x02 0x70018>;
		reset-names = "stmmaceth";
		snps,mixed-burst;
		snps,tso;
		tx-dma-size = <0x100>;
		rx-dma-size = <0x80>;
		snps,axi-config = <0x3e>;
		snps,mtl-rx-config = <0x3f>;
		snps,mtl-tx-config = <0x40>;
		phy-mode = "rmii";
		clock_in_out = "input";
		phy-handle = <0x41>;
		snps,flow-ctrl = <0x00>;
		nvmem-cells = <0x42>;
		nvmem-cell-names = "bgs";
		status = "okay";
		phandle = <0xa9>;

		mdio: mdio {
			compatible = "snps,dwmac-mdio";
			#address-cells = <0x01>;
			#size-cells = <0x00>;
			phandle = <0xaa>;

			rmii_phy: ethernet-phy@2 {
				compatible = "ethernet-phy-id0044.1400", "ethernet-phy-ieee802.3-c22";
				reg = <0x02>;
				clocks = <0x02 0x103>;
				resets = <0x02 0x7002d>;
				phy-is-integrated;
				nvmem-cells = <0x43>;
				nvmem-cell-names = "txlevel";
				bgs,increment = <0x00>;
				rockchip,thermal-zone = "soc-thermal";
				phandle = <0x41>;
			};
		};

		stmmac_axi_setup: stmmac-axi-config {
			snps,wr_osr_lmt = <0x04>;
			snps,rd_osr_lmt = <0x08>;
			snps,blen = <0x00 0x00 0x00 0x00 0x10 0x08 0x04>;
			phandle = <0x3e>;
		};

		mtl_rx_setup: rx-queues-config {
			snps,rx-queues-to-use = <0x01>;
			phandle = <0x3f>;

			queue0 {
				status = "okay";
			};
		};

		mtl_tx_setup: tx-queues-config {
			snps,tx-queues-to-use = <0x01>;
			phandle = <0x40>;

			queue0 {
				status = "okay";
			};
		};
	};

	emmc: mmc@ffa90000 {
		compatible = "rockchip,rv1106-dw-mshc", "rockchip,rk3288-dw-mshc";
		reg = <0xffa90000 0x4000>;
		interrupts = <0x00 0x30 0x04>;
		clocks = <0x02 0x26 0x02 0x25 0x3b 0x01 0x3b 0x02>;
		clock-names = "biu", "ciu", "ciu-drive", "ciu-sample";
		fifo-depth = <0x100>;
		max-frequency = <0xbebc200>;
		rockchip,use-v2-tuning;
		status = "disabled";
		phandle = <0xab>;
	};

	sdmmc: mmc@ffaa0000 {
		compatible = "rockchip,rv1106-dw-mshc", "rockchip,rk3288-dw-mshc";
		reg = <0xffaa0000 0x4000>;
		interrupts = <0x00 0x34 0x04>;
		clocks = <0x02 0xe8 0x02 0xe7 0x3b 0x03 0x3b 0x04>;
		clock-names = "biu", "ciu", "ciu-drive", "ciu-sample";
		fifo-depth = <0x100>;
		max-frequency = <0x2faf080>;
		status = "okay";
		no-sdio;
		no-mmc;
		bus-width = <0x04>;
		cap-mmc-highspeed;
		cap-sd-highspeed;
		disable-wp;
		no-1-8-v;
		pinctrl-names = "default";
		pinctrl-0 = <0x44 0x45 0x46 0x47>;
		phandle = <0xac>;
	};

	sfc: spi@ffac0000 {
		compatible = "rockchip,sfc";
		reg = <0xffac0000 0x4000>;
		interrupts = <0x00 0x35 0x04>;
		clocks = <0x02 0x3e 0x02 0x3d>;
		clock-names = "clk_sfc", "hclk_sfc";
		#address-cells = <0x01>;
		#size-cells = <0x00>;
		status = "okay";
		phandle = <0xad>;

		flash@0 {
			compatible = "spi-nand";
			reg = <0x00>;
			spi-max-frequency = <0x47868c0>;
			spi-rx-bus-width = <0x04>;
			spi-tx-bus-width = <0x01>;
		};
	};

	rve: rve@ffad0000 {
		compatible = "rockchip,rve";
		reg = <0xffad0000 0x1000>;
		interrupts = <0x00 0x6f 0x04>;
		clocks = <0x02 0x34 0x02 0x33>;
		clock-names = "aclk_rve", "hclk_rve";
		status = "okay";
		phandle = <0xae>;
	};

	i2s0_8ch: i2s@ffae0000 {
		compatible = "rockchip,rv1106-i2s-tdm";
		reg = <0xffae0000 0x1000>;
		interrupts = <0x00 0x50 0x04>;
		clocks = <0x02 0x9f 0x02 0x9e 0x02 0x31>;
		clock-names = "mclk_tx", "mclk_rx", "hclk";
		dmas = <0x2a 0x16 0x2a 0x15>;
		dma-names = "tx", "rx";
		resets = <0x02 0x4805f 0x02 0x48066>;
		reset-names = "tx-m", "rx-m";
		rockchip,clk-trcm = <0x01>;
		#sound-dai-cells = <0x00>;
		status = "disabled";
		phandle = <0xaf>;
	};

	usbdrd: usbdrd {
		compatible = "rockchip,rv1106-dwc3", "rockchip,rk3399-dwc3";
		clocks = <0x02 0x65 0x02 0x66 0x02 0x64>;
		clock-names = "ref", "utmi", "bus";
		#address-cells = <0x01>;
		#size-cells = <0x01>;
		ranges;
		status = "okay";
		phandle = <0xb0>;

		usbdrd_dwc3: usb@ffb00000 {
			compatible = "snps,dwc3";
			reg = <0xffb00000 0x100000>;
			interrupts = <0x00 0x36 0x04>;
			resets = <0x02 0x48047>;
			reset-names = "usb3-otg";
			dr_mode = "host";
			maximum-speed = "high-speed";
			phys = <0x48>;
			phy-names = "usb2-phy";
			phy_type = "utmi_wide";
			snps,dis_enblslpm_quirk;
			snps,dis-u2-freeclk-exists-quirk;
			snps,dis_u2_susphy_quirk;
			snps,dis-del-phy-power-chg-quirk;
			snps,dis-tx-ipgap-linecheck-quirk;
			snps,usb2-gadget-lpm-disable;
			snps,usb2-lpm-disable;
			snps,parkmode-disable-hs-quirk;
			status = "okay";
			extcon = <0x49>;
			phandle = <0xb1>;
		};
	};

	pinctrl: pinctrl {
		compatible = "rockchip,rv1106-pinctrl";
		rockchip,grf = <0x4a>;
		rockchip,pmu = <0x4b>;
		#address-cells = <0x01>;
		#size-cells = <0x01>;
		ranges;
		phandle = <0x4c>;

		gpio0: gpio@ff380000 {
			compatible = "rockchip,gpio-bank";
			reg = <0xff380000 0x100>;
			interrupts = <0x00 0x05 0x04>;
			clocks = <0x02 0x70 0x02 0x71>;
			gpio-controller;
			#gpio-cells = <0x02>;
			gpio-ranges = <0x4c 0x00 0x00 0x20>;
			interrupt-controller;
			#interrupt-cells = <0x02>;
			gpio-line-names = "", "SDMMC_PWREN", "PB_INT_N", "LED_STATUS", "PWR_KILL", "USBA_VBUS_EN", "USB_SEL", "", "", "", "", "", "", "", "", "", "", "", "", "", "", "", "", "", "", "", "", "", "", "", "", "";
			phandle = <0x58>;

			sdmmc-pwren-hog {
				gpio-hog;
				gpios = <0x01 0x00>;
				output-low;
				line-name = "SDMMC_PWREN";
			};
		};

		gpio1: gpio@ff530000 {
			compatible = "rockchip,gpio-bank";
			reg = <0xff530000 0x100>;
			interrupts = <0x00 0x07 0x04>;
			clocks = <0x02 0xd4 0x02 0xd5>;
			gpio-controller;
			#gpio-cells = <0x02>;
			gpio-ranges = <0x4c 0x00 0x20 0x20>;
			interrupt-controller;
			#interrupt-cells = <0x02>;
			gpio-line-names = "HDR_GPIO1_A0", "HDR_GPIO1_A1", "LED_ETH", "HDR_GPIO1_A3", "HDR_GPIO1_A4", "", "", "", "HDR_GPIO1_B0", "HDR_GPIO1_B1", "UART2_TX", "UART2_RX", "", "", "", "", "HDR_SPI0_CS0", "HDR_SPI0_SCLK", "HDR_SPI0_MOSI", "HDR_SPI0_MISO", "HDR_PWM8", "HDR_PWM9", "HDR_PWM10", "HDR_PWM11", "HDR_UART3_TX", "HDR_UART3_RX", "HDR_I2C3_SDA", "HDR_I2C3_SCL", "", "", "", "";
			phandle = <0x5c>;
		};

		gpio2: gpio@ff540000 {
			compatible = "rockchip,gpio-bank";
			reg = <0xff540000 0x100>;
			interrupts = <0x00 0x09 0x04>;
			clocks = <0x02 0xf9 0x02 0xfa>;
			gpio-controller;
			#gpio-cells = <0x02>;
			gpio-ranges = <0x4c 0x00 0x40 0x20>;
			interrupt-controller;
			#interrupt-cells = <0x02>;
			gpio-line-names = "HDR_GPIO2_A0", "HDR_GPIO2_A1", "HDR_GPIO2_A2", "HDR_GPIO2_A3", "HDR_GPIO2_A4", "HDR_GPIO2_A5", "HDR_GPIO2_A6", "HDR_GPIO2_A7", "HDR_I2C1_SCL", "HDR_I2C1_SDA", "", "", "", "", "", "", "", "", "", "", "", "", "", "", "", "", "", "", "", "", "", "";
			phandle = <0xb2>;
		};

		gpio3: gpio@ff550000 {
			compatible = "rockchip,gpio-bank";
			reg = <0xff550000 0x100>;
			interrupts = <0x00 0x0b 0x04>;
			clocks = <0x02 0xe1 0x02 0xe2>;
			gpio-controller;
			#gpio-cells = <0x02>;
			gpio-ranges = <0x4c 0x00 0x60 0x20>;
			interrupt-controller;
			#interrupt-cells = <0x02>;
			gpio-line-names = "", "SDMMC_DET", "SDMMC_D1", "SDMMC_D0", "SDMMC_CLK", "SDMMC_CMD", "SDMMC_D3", "SDMMC_D2", "", "", "", "", "", "", "", "", "", "", "", "", "", "", "", "", "", "", "", "", "", "", "", "";
			phandle = <0xb3>;
		};

		gpio4: gpio@ff560000 {
			compatible = "rockchip,gpio-bank";
			reg = <0xff560000 0x100>;
			interrupts = <0x00 0x0d 0x04>;
			clocks = <0x02 0x27 0x02 0x28>;
			gpio-controller;
			#gpio-cells = <0x02>;
			gpio-ranges = <0x4c 0x00 0x80 0x20>;
			interrupt-controller;
			#interrupt-cells = <0x02>;
			gpio-line-names = "", "", "FSPI_D2", "FSPI_D1", "FSPI_D0", "", "FSPI_D3", "", "FSPI_CS0N", "FSPI_CLK", "", "", "", "", "", "", "RECOVERY", "SARADC_IN1", "", "", "", "", "", "", "", "", "", "", "", "", "", "";
			phandle = <0xb4>;
		};

		pcfg_pull_up: pcfg-pull-up {
			bias-pull-up;
			phandle = <0x4f>;
		};

		pcfg_pull_down: pcfg-pull-down {
			bias-pull-down;
			phandle = <0x55>;
		};

		pcfg_pull_none: pcfg-pull-none {
			bias-disable;
			phandle = <0x4d>;
		};

		pcfg_pull_none_drv_level_0: pcfg-pull-none-drv-level-0 {
			bias-disable;
			drive-strength = <0x00>;
			phandle = <0xb5>;
		};

		pcfg_pull_none_drv_level_1: pcfg-pull-none-drv-level-1 {
			bias-disable;
			drive-strength = <0x01>;
			phandle = <0x54>;
		};

		pcfg_pull_none_drv_level_2: pcfg-pull-none-drv-level-2 {
			bias-disable;
			drive-strength = <0x02>;
			phandle = <0x53>;
		};

		pcfg_pull_none_drv_level_3: pcfg-pull-none-drv-level-3 {
			bias-disable;
			drive-strength = <0x03>;
			phandle = <0x52>;
		};

		pcfg_pull_none_drv_level_4: pcfg-pull-none-drv-level-4 {
			bias-disable;
			drive-strength = <0x04>;
			phandle = <0x51>;
		};

		pcfg_pull_none_drv_level_5: pcfg-pull-none-drv-level-5 {
			bias-disable;
			drive-strength = <0x05>;
			phandle = <0xb6>;
		};

		pcfg_pull_none_drv_level_6: pcfg-pull-none-drv-level-6 {
			bias-disable;
			drive-strength = <0x06>;
			phandle = <0xb7>;
		};

		pcfg_pull_none_drv_level_7: pcfg-pull-none-drv-level-7 {
			bias-disable;
			drive-strength = <0x07>;
			phandle = <0xb8>;
		};

		pcfg_pull_none_drv_level_8: pcfg-pull-none-drv-level-8 {
			bias-disable;
			drive-strength = <0x08>;
			phandle = <0xb9>;
		};

		pcfg_pull_none_drv_level_9: pcfg-pull-none-drv-level-9 {
			bias-disable;
			drive-strength = <0x09>;
			phandle = <0xba>;
		};

		pcfg_pull_none_drv_level_10: pcfg-pull-none-drv-level-10 {
			bias-disable;
			drive-strength = <0x0a>;
			phandle = <0xbb>;
		};

		pcfg_pull_none_drv_level_11: pcfg-pull-none-drv-level-11 {
			bias-disable;
			drive-strength = <0x0b>;
			phandle = <0xbc>;
		};

		pcfg_pull_none_drv_level_12: pcfg-pull-none-drv-level-12 {
			bias-disable;
			drive-strength = <0x0c>;
			phandle = <0xbd>;
		};

		pcfg_pull_none_drv_level_13: pcfg-pull-none-drv-level-13 {
			bias-disable;
			drive-strength = <0x0d>;
			phandle = <0xbe>;
		};

		pcfg_pull_none_drv_level_14: pcfg-pull-none-drv-level-14 {
			bias-disable;
			drive-strength = <0x0e>;
			phandle = <0xbf>;
		};

		pcfg_pull_none_drv_level_15: pcfg-pull-none-drv-level-15 {
			bias-disable;
			drive-strength = <0x0f>;
			phandle = <0xc0>;
		};

		pcfg_pull_up_drv_level_0: pcfg-pull-up-drv-level-0 {
			bias-pull-up;
			drive-strength = <0x00>;
			phandle = <0xc1>;
		};

		pcfg_pull_up_drv_level_1: pcfg-pull-up-drv-level-1 {
			bias-pull-up;
			drive-strength = <0x01>;
			phandle = <0xc2>;
		};

		pcfg_pull_up_drv_level_2: pcfg-pull-up-drv-level-2 {
			bias-pull-up;
			drive-strength = <0x02>;
			phandle = <0x4e>;
		};

		pcfg_pull_up_drv_level_3: pcfg-pull-up-drv-level-3 {
			bias-pull-up;
			drive-strength = <0x03>;
			phandle = <0xc3>;
		};

		pcfg_pull_up_drv_level_4: pcfg-pull-up-drv-level-4 {
			bias-pull-up;
			drive-strength = <0x04>;
			phandle = <0xc4>;
		};

		pcfg_pull_up_drv_level_5: pcfg-pull-up-drv-level-5 {
			bias-pull-up;
			drive-strength = <0x05>;
			phandle = <0xc5>;
		};

		pcfg_pull_up_drv_level_6: pcfg-pull-up-drv-level-6 {
			bias-pull-up;
			drive-strength = <0x06>;
			phandle = <0xc6>;
		};

		pcfg_pull_up_drv_level_7: pcfg-pull-up-drv-level-7 {
			bias-pull-up;
			drive-strength = <0x07>;
			phandle = <0xc7>;
		};

		pcfg_pull_up_drv_level_8: pcfg-pull-up-drv-level-8 {
			bias-pull-up;
			drive-strength = <0x08>;
			phandle = <0xc8>;
		};

		pcfg_pull_up_drv_level_9: pcfg-pull-up-drv-level-9 {
			bias-pull-up;
			drive-strength = <0x09>;
			phandle = <0xc9>;
		};

		pcfg_pull_up_drv_level_10: pcfg-pull-up-drv-level-10 {
			bias-pull-up;
			drive-strength = <0x0a>;
			phandle = <0xca>;
		};

		pcfg_pull_up_drv_level_11: pcfg-pull-up-drv-level-11 {
			bias-pull-up;
			drive-strength = <0x0b>;
			phandle = <0xcb>;
		};

		pcfg_pull_up_drv_level_12: pcfg-pull-up-drv-level-12 {
			bias-pull-up;
			drive-strength = <0x0c>;
			phandle = <0xcc>;
		};

		pcfg_pull_up_drv_level_13: pcfg-pull-up-drv-level-13 {
			bias-pull-up;
			drive-strength = <0x0d>;
			phandle = <0xcd>;
		};

		pcfg_pull_up_drv_level_14: pcfg-pull-up-drv-level-14 {
			bias-pull-up;
			drive-strength = <0x0e>;
			phandle = <0xce>;
		};

		pcfg_pull_up_drv_level_15: pcfg-pull-up-drv-level-15 {
			bias-pull-up;
			drive-strength = <0x0f>;
			phandle = <0xcf>;
		};

		pcfg_pull_down_drv_level_0: pcfg-pull-down-drv-level-0 {
			bias-pull-down;
			drive-strength = <0x00>;
			phandle = <0xd0>;
		};

		pcfg_pull_down_drv_level_1: pcfg-pull-down-drv-level-1 {
			bias-pull-down;
			drive-strength = <0x01>;
			phandle = <0xd1>;
		};

		pcfg_pull_down_drv_level_2: pcfg-pull-down-drv-level-2 {
			bias-pull-down;
			drive-strength = <0x02>;
			phandle = <0xd2>;
		};

		pcfg_pull_down_drv_level_3: pcfg-pull-down-drv-level-3 {
			bias-pull-down;
			drive-strength = <0x03>;
			phandle = <0xd3>;
		};

		pcfg_pull_down_drv_level_4: pcfg-pull-down-drv-level-4 {
			bias-pull-down;
			drive-strength = <0x04>;
			phandle = <0xd4>;
		};

		pcfg_pull_down_drv_level_5: pcfg-pull-down-drv-level-5 {
			bias-pull-down;
			drive-strength = <0x05>;
			phandle = <0xd5>;
		};

		pcfg_pull_down_drv_level_6: pcfg-pull-down-drv-level-6 {
			bias-pull-down;
			drive-strength = <0x06>;
			phandle = <0xd6>;
		};

		pcfg_pull_down_drv_level_7: pcfg-pull-down-drv-level-7 {
			bias-pull-down;
			drive-strength = <0x07>;
			phandle = <0xd7>;
		};

		pcfg_pull_down_drv_level_8: pcfg-pull-down-drv-level-8 {
			bias-pull-down;
			drive-strength = <0x08>;
			phandle = <0xd8>;
		};

		pcfg_pull_down_drv_level_9: pcfg-pull-down-drv-level-9 {
			bias-pull-down;
			drive-strength = <0x09>;
			phandle = <0xd9>;
		};

		pcfg_pull_down_drv_level_10: pcfg-pull-down-drv-level-10 {
			bias-pull-down;
			drive-strength = <0x0a>;
			phandle = <0xda>;
		};

		pcfg_pull_down_drv_level_11: pcfg-pull-down-drv-level-11 {
			bias-pull-down;
			drive-strength = <0x0b>;
			phandle = <0xdb>;
		};

		pcfg_pull_down_drv_level_12: pcfg-pull-down-drv-level-12 {
			bias-pull-down;
			drive-strength = <0x0c>;
			phandle = <0xdc>;
		};

		pcfg_pull_down_drv_level_13: pcfg-pull-down-drv-level-13 {
			bias-pull-down;
			drive-strength = <0x0d>;
			phandle = <0xdd>;
		};

		pcfg_pull_down_drv_level_14: pcfg-pull-down-drv-level-14 {
			bias-pull-down;
			drive-strength = <0x0e>;
			phandle = <0xde>;
		};

		pcfg_pull_down_drv_level_15: pcfg-pull-down-drv-level-15 {
			bias-pull-down;
			drive-strength = <0x0f>;
			phandle = <0xdf>;
		};

		pcfg_pull_up_smt: pcfg-pull-up-smt {
			bias-pull-up;
			input-schmitt-enable;
			phandle = <0xe0>;
		};

		pcfg_pull_down_smt: pcfg-pull-down-smt {
			bias-pull-down;
			input-schmitt-enable;
			phandle = <0xe1>;
		};

		pcfg_pull_none_smt: pcfg-pull-none-smt {
			bias-disable;
			input-schmitt-enable;
			phandle = <0x50>;
		};

		pcfg_pull_none_drv_level_0_smt: pcfg-pull-none-drv-level-0-smt {
			bias-disable;
			drive-strength = <0x00>;
			input-schmitt-enable;
			phandle = <0xe2>;
		};

		pcfg_output_high: pcfg-output-high {
			output-high;
			phandle = <0xe3>;
		};

		pcfg_output_high_pull_up: pcfg-output-high-pull-up {
			output-high;
			bias-pull-up;
			phandle = <0xe4>;
		};

		pcfg_output_high_pull_down: pcfg-output-high-pull-down {
			output-high;
			bias-pull-down;
			phandle = <0xe5>;
		};

		pcfg_output_high_pull_none: pcfg-output-high-pull-none {
			output-high;
			bias-disable;
			phandle = <0xe6>;
		};

		pcfg_output_low: pcfg-output-low {
			output-low;
			phandle = <0xe7>;
		};

		pcfg_output_low_pull_up: pcfg-output-low-pull-up {
			output-low;
			bias-pull-up;
			phandle = <0xe8>;
		};

		pcfg_output_low_pull_down: pcfg-output-low-pull-down {
			output-low;
			bias-pull-down;
			phandle = <0xe9>;
		};

		pcfg_output_low_pull_none: pcfg-output-low-pull-none {
			output-low;
			bias-disable;
			phandle = <0xea>;
		};

		adc {

			adc_pins: adc-pins {
				rockchip,pins = <0x04 0x10 0x01 0x4d 0x04 0x11 0x01 0x4d>;
				phandle = <0xeb>;
			};
		};

		avs {

			avs_pins: avs-pins {
				rockchip,pins = <0x01 0x02 0x02 0x4d>;
				phandle = <0xec>;
			};
		};

		clk {

			clk_32k: clk-32k {
				rockchip,pins = <0x00 0x00 0x02 0x4d>;
				phandle = <0xed>;
			};

			clk_refout: clk-refout {
				rockchip,pins = <0x00 0x00 0x03 0x4d>;
				phandle = <0xee>;
			};
		};

		dsmaudio {

			dsmaudio_pins: dsmaudio-pins {
				rockchip,pins = <0x01 0x1b 0x07 0x4d 0x01 0x1a 0x07 0x4d>;
				phandle = <0x19>;
			};
		};

		emmc {

			emmc_bus8: emmc-bus8 {
				rockchip,pins = <0x04 0x04 0x01 0x4e 0x04 0x03 0x01 0x4e 0x04 0x02 0x01 0x4e 0x04 0x06 0x01 0x4e 0x04 0x05 0x01 0x4e 0x04 0x07 0x01 0x4e 0x04 0x01 0x01 0x4e 0x04 0x00 0x01 0x4e>;
				phandle = <0xef>;
			};

			emmc_clk: emmc-clk {
				rockchip,pins = <0x04 0x09 0x01 0x4e>;
				phandle = <0xf0>;
			};

			emmc_cmd: emmc-cmd {
				rockchip,pins = <0x04 0x08 0x01 0x4e>;
				phandle = <0xf1>;
			};
		};

		flash {

			flash_pins: flash-pins {
				rockchip,pins = <0x02 0x06 0x06 0x4d>;
				phandle = <0xf2>;
			};
		};

		fspi {

			fspi_pins: fspi-pins {
				rockchip,pins = <0x04 0x09 0x02 0x4e 0x04 0x04 0x02 0x4d 0x04 0x03 0x02 0x4d 0x04 0x02 0x02 0x4d 0x04 0x06 0x02 0x4d>;
				phandle = <0xf3>;
			};

			fspi_cs0: fspi-cs0 {
				rockchip,pins = <0x04 0x08 0x02 0x4f>;
				phandle = <0xf4>;
			};
		};

		hpmcu {

			hpmcum0_pins: hpmcum0-pins {
				rockchip,pins = <0x01 0x0a 0x03 0x4d 0x01 0x0b 0x03 0x4d>;
				phandle = <0xf5>;
			};

			hpmcum1_pins: hpmcum1-pins {
				rockchip,pins = <0x03 0x07 0x04 0x4d 0x03 0x06 0x04 0x4d>;
				phandle = <0xf6>;
			};
		};

		i2c0 {

			i2c0m0_xfer: i2c0m0-xfer {
				rockchip,pins = <0x01 0x03 0x02 0x50 0x01 0x04 0x02 0x50>;
				phandle = <0x17>;
			};

			i2c0m1_xfer: i2c0m1-xfer {
				rockchip,pins = <0x04 0x01 0x04 0x50 0x04 0x00 0x04 0x50>;
				phandle = <0xf7>;
			};

			i2c0m2_xfer: i2c0m2-xfer {
				rockchip,pins = <0x03 0x04 0x03 0x50 0x03 0x05 0x03 0x50>;
				phandle = <0xf8>;
			};
		};

		i2c1 {

			i2c1m0_xfer: i2c1m0-xfer {
				rockchip,pins = <0x00 0x05 0x01 0x50 0x00 0x06 0x01 0x50>;
				phandle = <0xf9>;
			};

			i2c1m1_xfer: i2c1m1-xfer {
				rockchip,pins = <0x02 0x08 0x02 0x50 0x02 0x09 0x02 0x50>;
				phandle = <0x18>;
			};
		};

		i2c2 {

			i2c2m0_xfer: i2c2m0-xfer {
				rockchip,pins = <0x01 0x00 0x02 0x50 0x01 0x01 0x02 0x50>;
				phandle = <0x23>;
			};

			i2c2m1_xfer: i2c2m1-xfer {
				rockchip,pins = <0x04 0x07 0x04 0x50 0x04 0x05 0x04 0x50>;
				phandle = <0xfa>;
			};
		};

		i2c3 {

			i2c3m0_xfer: i2c3m0-xfer {
				rockchip,pins = <0x02 0x06 0x05 0x50 0x02 0x07 0x05 0x50>;
				phandle = <0xfb>;
			};

			i2c3m1_xfer: i2c3m1-xfer {
				rockchip,pins = <0x01 0x1b 0x03 0x50 0x01 0x1a 0x03 0x50>;
				phandle = <0x24>;
			};

			i2c3m2_xfer: i2c3m2-xfer {
				rockchip,pins = <0x03 0x19 0x03 0x50 0x03 0x1a 0x03 0x50>;
				phandle = <0xfc>;
			};
		};

		i2c4 {

			i2c4m0_xfer: i2c4m0-xfer {
				rockchip,pins = <0x02 0x01 0x05 0x50 0x02 0x00 0x05 0x50>;
				phandle = <0x25>;
			};

			i2c4m1_xfer: i2c4m1-xfer {
				rockchip,pins = <0x01 0x12 0x04 0x50 0x01 0x13 0x04 0x50>;
				phandle = <0xfd>;
			};

			i2c4m2_xfer: i2c4m2-xfer {
				rockchip,pins = <0x03 0x17 0x03 0x50 0x03 0x18 0x03 0x50>;
				phandle = <0xfe>;
			};
		};

		i2s0 {

			i2s0_pins: i2s0-pins {
				rockchip,pins = <0x02 0x01 0x02 0x4d 0x02 0x02 0x02 0x4d 0x02 0x00 0x02 0x4d 0x02 0x05 0x02 0x4d 0x02 0x04 0x02 0x4d 0x02 0x07 0x02 0x4d 0x02 0x06 0x02 0x4d 0x02 0x03 0x02 0x4d>;
				phandle = <0xff>;
			};
		};

		lcd {

			lcd_pins: lcd-pins {
				rockchip,pins = <0x01 0x1b 0x01 0x51 0x01 0x17 0x01 0x52 0x01 0x16 0x01 0x52 0x01 0x15 0x01 0x52 0x01 0x14 0x01 0x52 0x01 0x13 0x01 0x52 0x01 0x12 0x01 0x52 0x01 0x11 0x01 0x52 0x01 0x10 0x01 0x52 0x02 0x00 0x03 0x52 0x02 0x01 0x03 0x52 0x02 0x02 0x03 0x52 0x02 0x03 0x03 0x52 0x02 0x04 0x03 0x52 0x02 0x05 0x03 0x52 0x02 0x06 0x03 0x52 0x02 0x07 0x03 0x52 0x02 0x08 0x03 0x52 0x02 0x09 0x03 0x52 0x01 0x18 0x01 0x52 0x01 0x19 0x01 0x52 0x01 0x1a 0x01 0x52>;
				phandle = <0x100>;
			};

			bt1120_pins: bt1120-pins {
				rockchip,pins = <0x01 0x1b 0x01 0x52 0x01 0x17 0x01 0x53 0x01 0x16 0x01 0x53 0x01 0x15 0x01 0x53 0x01 0x14 0x01 0x53 0x01 0x13 0x01 0x53 0x01 0x12 0x01 0x53 0x01 0x11 0x01 0x53 0x01 0x10 0x01 0x53 0x02 0x00 0x03 0x53 0x02 0x01 0x03 0x53 0x02 0x02 0x03 0x53 0x02 0x03 0x03 0x53 0x02 0x04 0x03 0x53 0x02 0x05 0x03 0x53 0x02 0x06 0x03 0x53 0x02 0x07 0x03 0x53>;
				phandle = <0x101>;
			};

			bt656_pins: bt656-pins {
				rockchip,pins = <0x01 0x1b 0x01 0x53 0x01 0x17 0x01 0x54 0x01 0x16 0x01 0x54 0x01 0x15 0x01 0x54 0x01 0x14 0x01 0x54 0x01 0x13 0x01 0x54 0x01 0x12 0x01 0x54 0x01 0x11 0x01 0x54 0x01 0x10 0x01 0x54>;
				phandle = <0x102>;
			};

			rgb3x8_pins: rgb3x8-pins {
				rockchip,pins = <0x01 0x1b 0x01 0x51 0x01 0x17 0x01 0x52 0x01 0x16 0x01 0x52 0x01 0x15 0x01 0x52 0x01 0x14 0x01 0x52 0x01 0x13 0x01 0x52 0x01 0x12 0x01 0x52 0x01 0x11 0x01 0x52 0x01 0x10 0x01 0x52 0x01 0x18 0x01 0x52 0x01 0x19 0x01 0x52 0x01 0x1a 0x01 0x52>;
				phandle = <0x103>;
			};

			rgb565_pins: rgb565-pins {
				rockchip,pins = <0x01 0x1b 0x01 0x51 0x01 0x17 0x01 0x52 0x01 0x16 0x01 0x52 0x01 0x15 0x01 0x52 0x01 0x14 0x01 0x52 0x01 0x13 0x01 0x52 0x01 0x12 0x01 0x52 0x01 0x11 0x01 0x52 0x01 0x10 0x01 0x52 0x02 0x00 0x03 0x52 0x02 0x01 0x03 0x52 0x02 0x02 0x03 0x52 0x02 0x03 0x03 0x52 0x02 0x04 0x03 0x52 0x02 0x05 0x03 0x52 0x02 0x06 0x03 0x52 0x02 0x07 0x03 0x52 0x01 0x18 0x01 0x52 0x01 0x19 0x01 0x52 0x01 0x1a 0x01 0x52>;
				phandle = <0x104>;
			};
		};

		lpmcu {

			lpmcum0_pins: lpmcum0-pins {
				rockchip,pins = <0x01 0x0a 0x04 0x4d 0x01 0x0b 0x04 0x4d>;
				phandle = <0x105>;
			};

			lpmcum1_pins: lpmcum1-pins {
				rockchip,pins = <0x03 0x04 0x04 0x4d 0x03 0x05 0x04 0x4d>;
				phandle = <0x106>;
			};
		};

		mipi {

			mipi_pins: mipi-pins {
				rockchip,pins = <0x03 0x10 0x02 0x4d 0x03 0x11 0x02 0x4d 0x03 0x0a 0x02 0x4d 0x03 0x0b 0x02 0x4d 0x03 0x12 0x02 0x4d 0x03 0x13 0x02 0x4d 0x03 0x0e 0x02 0x4d 0x03 0x0f 0x02 0x4d 0x03 0x0c 0x02 0x4d 0x03 0x0d 0x02 0x4d 0x03 0x08 0x02 0x4d 0x03 0x09 0x02 0x4d>;
				phandle = <0x107>;
			};

			mipi_refclk_out0: mipi-refclk-out0 {
				rockchip,pins = <0x03 0x14 0x02 0x4d>;
				phandle = <0x108>;
			};

			mipi_refclk_out1: mipi-refclk-out1 {
				rockchip,pins = <0x03 0x16 0x03 0x4d>;
				phandle = <0x109>;
			};
		};

		pmic {

			pmicm0_pins: pmicm0-pins {
				rockchip,pins = <0x00 0x04 0x01 0x4d>;
				phandle = <0x10a>;
			};

			pmicm1_pins: pmicm1-pins {
				rockchip,pins = <0x00 0x03 0x01 0x4d>;
				phandle = <0x10b>;
			};
		};

		pmu {

			pmu_pins: pmu-pins {
				rockchip,pins = <0x01 0x01 0x03 0x4d>;
				phandle = <0x10c>;
			};
		};

		prelight {

			prelight_pins: prelight-pins {
				rockchip,pins = <0x02 0x07 0x06 0x4d>;
				phandle = <0x10d>;
			};
		};

		pwm0 {

			pwm0m0_pins: pwm0m0-pins {
				rockchip,pins = <0x01 0x02 0x01 0x4d>;
				phandle = <0x1a>;
			};

			pwm0m1_pins: pwm0m1-pins {
				rockchip,pins = <0x01 0x1a 0x06 0x4d>;
				phandle = <0x10e>;
			};
		};

		pwm1 {

			pwm1m0_pins: pwm1m0-pins {
				rockchip,pins = <0x00 0x04 0x02 0x4d>;
				phandle = <0x1b>;
			};

			pwm1m1_pins: pwm1m1-pins {
				rockchip,pins = <0x04 0x11 0x02 0x4d>;
				phandle = <0x10f>;
			};

			pwm1m2_pins: pwm1m2-pins {
				rockchip,pins = <0x03 0x1b 0x02 0x4d>;
				phandle = <0x110>;
			};
		};

		pwm2 {

			pwm2m0_pins: pwm2m0-pins {
				rockchip,pins = <0x00 0x01 0x02 0x4d>;
				phandle = <0x1c>;
			};

			pwm2m1_pins: pwm2m1-pins {
				rockchip,pins = <0x02 0x06 0x04 0x4d>;
				phandle = <0x111>;
			};

			pwm2m2_pins: pwm2m2-pins {
				rockchip,pins = <0x01 0x10 0x03 0x4d>;
				phandle = <0x112>;
			};
		};

		pwm3 {

			pwm3m0_pins: pwm3m0-pins {
				rockchip,pins = <0x00 0x02 0x01 0x4d>;
				phandle = <0x1d>;
			};

			pwm3m1_pins: pwm3m1-pins {
				rockchip,pins = <0x01 0x08 0x02 0x4d>;
				phandle = <0x113>;
			};

			pwm3m2_pins: pwm3m2-pins {
				rockchip,pins = <0x01 0x18 0x03 0x4d>;
				phandle = <0x114>;
			};
		};

		pwm4 {

			pwm4m0_pins: pwm4m0-pins {
				rockchip,pins = <0x01 0x01 0x04 0x4d>;
				phandle = <0x1e>;
			};

			pwm4m1_pins: pwm4m1-pins {
				rockchip,pins = <0x02 0x07 0x04 0x4d>;
				phandle = <0x115>;
			};

			pwm4m2_pins: pwm4m2-pins {
				rockchip,pins = <0x01 0x11 0x03 0x4d>;
				phandle = <0x116>;
			};
		};

		pwm5 {

			pwm5m0_pins: pwm5m0-pins {
				rockchip,pins = <0x00 0x05 0x03 0x4d>;
				phandle = <0x1f>;
			};

			pwm5m1_pins: pwm5m1-pins {
				rockchip,pins = <0x02 0x08 0x04 0x4d>;
				phandle = <0x117>;
			};

			pwm5m2_pins: pwm5m2-pins {
				rockchip,pins = <0x01 0x12 0x03 0x4d>;
				phandle = <0x118>;
			};
		};

		pwm6 {

			pwm6m0_pins: pwm6m0-pins {
				rockchip,pins = <0x00 0x06 0x03 0x4d>;
				phandle = <0x20>;
			};

			pwm6m1_pins: pwm6m1-pins {
				rockchip,pins = <0x02 0x09 0x04 0x4d>;
				phandle = <0x119>;
			};

			pwm6m2_pins: pwm6m2-pins {
				rockchip,pins = <0x01 0x13 0x03 0x4d>;
				phandle = <0x11a>;
			};
		};

		pwm7 {

			pwm7m0_pins: pwm7m0-pins {
				rockchip,pins = <0x01 0x00 0x03 0x4d>;
				phandle = <0x21>;
			};

			pwm7m1_pins: pwm7m1-pins {
				rockchip,pins = <0x01 0x09 0x02 0x4d>;
				phandle = <0x11b>;
			};

			pwm7m2_pins: pwm7m2-pins {
				rockchip,pins = <0x03 0x16 0x02 0x4d>;
				phandle = <0x11c>;
			};
		};

		pwm8 {

			pwm8m0_pins: pwm8m0-pins {
				rockchip,pins = <0x03 0x03 0x04 0x4d>;
				phandle = <0x11d>;
			};

			pwm8m1_pins: pwm8m1-pins {
				rockchip,pins = <0x01 0x14 0x03 0x4d>;
				phandle = <0x26>;
			};
		};

		pwm9 {

			pwm9m0_pins: pwm9m0-pins {
				rockchip,pins = <0x03 0x02 0x04 0x4d>;
				phandle = <0x11e>;
			};

			pwm9m1_pins: pwm9m1-pins {
				rockchip,pins = <0x01 0x15 0x03 0x4d>;
				phandle = <0x27>;
			};
		};

		pwm10 {

			pwm10m0_pins: pwm10m0-pins {
				rockchip,pins = <0x03 0x04 0x05 0x4d>;
				phandle = <0x11f>;
			};

			pwm10m1_pins: pwm10m1-pins {
				rockchip,pins = <0x01 0x16 0x03 0x4d>;
				phandle = <0x28>;
			};

			pwm10m2_pins: pwm10m2-pins {
				rockchip,pins = <0x01 0x19 0x03 0x4d>;
				phandle = <0x120>;
			};
		};

		pwm11 {

			pwm11m0_pins: pwm11m0-pins {
				rockchip,pins = <0x03 0x05 0x05 0x4d>;
				phandle = <0x121>;
			};

			pwm11m1_pins: pwm11m1-pins {
				rockchip,pins = <0x01 0x17 0x03 0x4d>;
				phandle = <0x29>;
			};

			pwm11m2_pins: pwm11m2-pins {
				rockchip,pins = <0x01 0x1b 0x05 0x4d>;
				phandle = <0x122>;
			};
		};

		rtc {

			rtc_pins: rtc-pins {
				rockchip,pins = <0x00 0x00 0x04 0x4d>;
				phandle = <0x123>;
			};
		};

		sdmmc0 {

			sdmmc0_bus4: sdmmc0-bus4 {
				rockchip,pins = <0x03 0x03 0x01 0x4e 0x03 0x02 0x01 0x4e 0x03 0x07 0x01 0x4e 0x03 0x06 0x01 0x4e>;
				phandle = <0x47>;
			};

			sdmmc0_clk: sdmmc0-clk {
				rockchip,pins = <0x03 0x04 0x01 0x4e>;
				phandle = <0x44>;
			};

			sdmmc0_cmd: sdmmc0-cmd {
				rockchip,pins = <0x03 0x05 0x01 0x4e>;
				phandle = <0x45>;
			};

			sdmmc0_det: sdmmc0-det {
				rockchip,pins = <0x03 0x01 0x01 0x4f>;
				phandle = <0x46>;
			};

			sdmmc0_idle_pins: sdmmc0-idle-pins {
				rockchip,pins = <0x03 0x02 0x00 0x55 0x03 0x03 0x00 0x55 0x03 0x04 0x00 0x55 0x03 0x05 0x00 0x55 0x03 0x06 0x00 0x55 0x03 0x07 0x00 0x55>;
				phandle = <0x124>;
			};
		};

		sdmmc1 {

			sdmmc1m0_bus1: sdmmc1m0-bus1 {
				rockchip,pins = <0x02 0x01 0x01 0x4e>;
				phandle = <0x125>;
			};

			sdmmc1m0_bus4: sdmmc1m0-bus4 {
				rockchip,pins = <0x02 0x01 0x01 0x4e 0x02 0x00 0x01 0x4e 0x02 0x05 0x01 0x4e 0x02 0x04 0x01 0x4e>;
				phandle = <0x126>;
			};

			sdmmc1m0_clk: sdmmc1m0-clk {
				rockchip,pins = <0x02 0x02 0x01 0x4e>;
				phandle = <0x127>;
			};

			sdmmc1m0_cmd: sdmmc1m0-cmd {
				rockchip,pins = <0x02 0x03 0x01 0x4e>;
				phandle = <0x128>;
			};

			sdmmc1m0_idle_pins: sdmmc1m0-idle-pins {
				rockchip,pins = <0x02 0x00 0x00 0x55 0x02 0x01 0x00 0x55 0x02 0x02 0x00 0x55 0x02 0x03 0x00 0x55 0x02 0x04 0x00 0x55 0x02 0x05 0x00 0x55>;
				phandle = <0x129>;
			};

			sdmmc1m1_bus4: sdmmc1m1-bus4 {
				rockchip,pins = <0x01 0x11 0x05 0x4e 0x01 0x10 0x05 0x4e 0x01 0x15 0x05 0x4e 0x01 0x14 0x05 0x4e>;
				phandle = <0x12a>;
			};

			sdmmc1m1_clk: sdmmc1m1-clk {
				rockchip,pins = <0x01 0x12 0x05 0x4e>;
				phandle = <0x12b>;
			};

			sdmmc1m1_cmd: sdmmc1m1-cmd {
				rockchip,pins = <0x01 0x13 0x05 0x4e>;
				phandle = <0x12c>;
			};

			sdmmc1m1_idle_pins: sdmmc1m1-idle-pins {
				rockchip,pins = <0x01 0x10 0x00 0x55 0x01 0x11 0x00 0x55 0x01 0x12 0x00 0x55 0x01 0x13 0x00 0x55 0x01 0x14 0x00 0x55 0x01 0x15 0x00 0x55>;
				phandle = <0x12d>;
			};
		};

		spi0 {

			spi0m0_pins: spi0m0-pins {
				rockchip,pins = <0x01 0x11 0x04 0x4d 0x01 0x13 0x06 0x4d 0x01 0x12 0x06 0x4d>;
				phandle = <0x35>;
			};

			spi0m0_cs0: spi0m0-cs0 {
				rockchip,pins = <0x01 0x10 0x04 0x4d>;
				phandle = <0x36>;
			};

			spi0m0_cs1: spi0m0-cs1 {
				rockchip,pins = <0x01 0x1a 0x05 0x4d>;
				phandle = <0x12e>;
			};
		};

		spi1 {

			spi1m0_pins: spi1m0-pins {
				rockchip,pins = <0x04 0x07 0x02 0x4d 0x04 0x00 0x02 0x4d 0x04 0x01 0x02 0x4d>;
				phandle = <0x39>;
			};

			spi1m0_cs0: spi1m0-cs0 {
				rockchip,pins = <0x04 0x05 0x02 0x4d>;
				phandle = <0x37>;
			};

			spi1m0_cs1: spi1m0-cs1 {
				rockchip,pins = <0x01 0x09 0x03 0x4d>;
				phandle = <0x38>;
			};
		};

		uart0 {

			uart0m0_xfer: uart0m0-xfer {
				rockchip,pins = <0x00 0x00 0x01 0x4f 0x00 0x01 0x01 0x4f>;
				phandle = <0x2b>;
			};

			uart0m1_xfer: uart0m1-xfer {
				rockchip,pins = <0x02 0x08 0x01 0x4f 0x02 0x09 0x01 0x4f>;
				phandle = <0x12f>;
			};

			uart0m1_ctsn: uart0m1-ctsn {
				rockchip,pins = <0x02 0x07 0x01 0x4d>;
				phandle = <0x130>;
			};

			uart0m1_rtsn: uart0m1-rtsn {
				rockchip,pins = <0x02 0x06 0x01 0x4d>;
				phandle = <0x131>;
			};

			uart0m2_xfer: uart0m2-xfer {
				rockchip,pins = <0x04 0x00 0x03 0x4f 0x04 0x01 0x03 0x4f>;
				phandle = <0x132>;
			};
		};

		uart1 {

			uart1m0_xfer: uart1m0-xfer {
				rockchip,pins = <0x01 0x04 0x01 0x4f 0x01 0x03 0x01 0x4f>;
				phandle = <0x2c>;
			};

			uart1m0_ctsn: uart1m0-ctsn {
				rockchip,pins = <0x00 0x06 0x02 0x4d>;
				phandle = <0x2d>;
			};

			uart1m0_rtsn: uart1m0-rtsn {
				rockchip,pins = <0x00 0x05 0x02 0x4d>;
				phandle = <0x2e>;
			};

			uart1m1_xfer: uart1m1-xfer {
				rockchip,pins = <0x02 0x05 0x04 0x4f 0x02 0x04 0x04 0x4f>;
				phandle = <0x133>;
			};

			uart1m1_ctsn: uart1m1-ctsn {
				rockchip,pins = <0x02 0x00 0x04 0x4d>;
				phandle = <0x134>;
			};

			uart1m1_rtsn: uart1m1-rtsn {
				rockchip,pins = <0x02 0x01 0x04 0x4d>;
				phandle = <0x135>;
			};

			uart1m2_xfer: uart1m2-xfer {
				rockchip,pins = <0x04 0x07 0x03 0x4f 0x04 0x05 0x03 0x4f>;
				phandle = <0x136>;
			};
		};

		uart2 {

			uart2m0_xfer: uart2m0-xfer {
				rockchip,pins = <0x03 0x03 0x02 0x4f 0x03 0x02 0x02 0x4f>;
				phandle = <0x137>;
			};

			uart2m1_xfer: uart2m1-xfer {
				rockchip,pins = <0x01 0x0b 0x02 0x4f 0x01 0x0a 0x02 0x4f>;
				phandle = <0x2f>;
			};
		};

		uart3 {

			uart3m0_xfer: uart3m0-xfer {
				rockchip,pins = <0x01 0x01 0x01 0x4f 0x01 0x00 0x01 0x4f>;
				phandle = <0x138>;
			};

			uart3m1_xfer: uart3m1-xfer {
				rockchip,pins = <0x01 0x19 0x05 0x4f 0x01 0x18 0x05 0x4f>;
				phandle = <0x30>;
			};
		};

		uart4 {

			uart4m0_xfer: uart4m0-xfer {
				rockchip,pins = <0x01 0x08 0x01 0x4f 0x01 0x09 0x01 0x4f>;
				phandle = <0x31>;
			};

			uart4m1_xfer: uart4m1-xfer {
				rockchip,pins = <0x01 0x14 0x04 0x4f 0x01 0x15 0x04 0x4f>;
				phandle = <0x139>;
			};

			uart4m1_ctsn: uart4m1-ctsn {
				rockchip,pins = <0x01 0x17 0x04 0x4d>;
				phandle = <0x13a>;
			};

			uart4m1_rtsn: uart4m1-rtsn {
				rockchip,pins = <0x01 0x16 0x04 0x4d>;
				phandle = <0x13b>;
			};
		};

		uart5 {

			uart5m0_xfer: uart5m0-xfer {
				rockchip,pins = <0x03 0x07 0x02 0x4f 0x03 0x06 0x02 0x4f>;
				phandle = <0x32>;
			};

			uart5m0_ctsn: uart5m0-ctsn {
				rockchip,pins = <0x03 0x05 0x02 0x4d>;
				phandle = <0x33>;
			};

			uart5m0_rtsn: uart5m0-rtsn {
				rockchip,pins = <0x03 0x04 0x02 0x4d>;
				phandle = <0x34>;
			};

			uart5m1_xfer: uart5m1-xfer {
				rockchip,pins = <0x01 0x1a 0x04 0x4f 0x01 0x1b 0x04 0x4f>;
				phandle = <0x13c>;
			};

			uart5m1_ctsn: uart5m1-ctsn {
				rockchip,pins = <0x01 0x19 0x04 0x4d>;
				phandle = <0x13d>;
			};

			uart5m1_rtsn: uart5m1-rtsn {
				rockchip,pins = <0x01 0x18 0x04 0x4d>;
				phandle = <0x13e>;
			};

			uart5m2_xfer: uart5m2-xfer {
				rockchip,pins = <0x03 0x18 0x02 0x4f 0x03 0x17 0x02 0x4f>;
				phandle = <0x13f>;
			};

			uart5m2_ctsn: uart5m2-ctsn {
				rockchip,pins = <0x03 0x1a 0x02 0x4d>;
				phandle = <0x140>;
			};

			uart5m2_rtsn: uart5m2-rtsn {
				rockchip,pins = <0x03 0x19 0x02 0x4d>;
				phandle = <0x141>;
			};
		};

		vicap {

			vicapm0_pins: vicapm0-pins {
				rockchip,pins = <0x03 0x12 0x01 0x4d 0x03 0x08 0x01 0x4d 0x03 0x09 0x01 0x4d 0x03 0x0a 0x01 0x4d 0x03 0x0b 0x01 0x4d 0x03 0x0c 0x01 0x4d 0x03 0x0d 0x01 0x4d 0x03 0x0e 0x01 0x4d 0x03 0x0f 0x01 0x4d 0x03 0x10 0x01 0x4d 0x03 0x11 0x01 0x4d 0x03 0x13 0x01 0x4d 0x03 0x15 0x01 0x4d>;
				phandle = <0x142>;
			};

			vicapm1_pins: vicapm1-pins {
				rockchip,pins = <0x01 0x18 0x02 0x4d 0x01 0x02 0x03 0x4d 0x01 0x09 0x04 0x4d 0x01 0x10 0x02 0x4d 0x01 0x11 0x02 0x4d 0x01 0x12 0x02 0x4d 0x01 0x13 0x02 0x4d 0x01 0x14 0x02 0x4d 0x01 0x15 0x02 0x4d 0x01 0x16 0x02 0x4d 0x01 0x17 0x02 0x4d 0x01 0x19 0x02 0x4d 0x01 0x1a 0x02 0x4d>;
				phandle = <0x143>;
			};

			vicap_d10: vicap-d10 {
				rockchip,pins = <0x03 0x16 0x01 0x4d>;
				phandle = <0x144>;
			};

			vicap_d11: vicap-d11 {
				rockchip,pins = <0x03 0x17 0x01 0x4d>;
				phandle = <0x145>;
			};

			vicap_d12: vicap-d12 {
				rockchip,pins = <0x03 0x18 0x01 0x4d>;
				phandle = <0x146>;
			};

			vicap_d13: vicap-d13 {
				rockchip,pins = <0x03 0x19 0x01 0x4d>;
				phandle = <0x147>;
			};

			vicap_d14: vicap-d14 {
				rockchip,pins = <0x03 0x1a 0x01 0x4d>;
				phandle = <0x148>;
			};

			vicap_d15: vicap-d15 {
				rockchip,pins = <0x03 0x1b 0x01 0x4d>;
				phandle = <0x149>;
			};

			vicap_clkout_m0: vicap-clkout-m0 {
				rockchip,pins = <0x03 0x14 0x01 0x4d>;
				phandle = <0x14a>;
			};

			vicap_clkout_m1: vicap-clkout-m1 {
				rockchip,pins = <0x01 0x1b 0x02 0x4d>;
				phandle = <0x14b>;
			};
		};

		board-gpio {

			pb_int_n_pin: pb-int-n-pin {
				rockchip,pins = <0x00 0x02 0x00 0x4d>;
				phandle = <0x57>;
			};

			pwr_kill_pin: pwr-kill-pin {
				rockchip,pins = <0x00 0x04 0x00 0x55>;
				phandle = <0x59>;
			};

			led_status_pin: led-status-pin {
				rockchip,pins = <0x00 0x03 0x00 0x4d>;
				phandle = <0x5a>;
			};

			led_eth_pin: led-eth-pin {
				rockchip,pins = <0x01 0x02 0x00 0x4d>;
				phandle = <0x5b>;
			};
		};
	};

	rockchip_amp: rockchip-amp {
		compatible = "rockchip,amp";
		clocks = <0x02 0x3b 0x02 0x53 0x02 0x59 0x02 0x5f 0x02 0x42 0x02 0x123>;
		status = "okay";
		phandle = <0x14c>;
	};

	adc-keys {
		compatible = "adc-keys";
		io-channels = <0x56 0x00>;
		io-channel-names = "buttons";
		poll-interval = <0x64>;
		keyup-threshold-microvolt = <0x1b7740>;

		key_volumeup-key {
			label = "key_volumeup";
			linux,code = <0x73>;
			press-threshold-microvolt = <0x00>;
		};

		key_volumedown-key {
			label = "key_volumedown";
			linux,code = <0x72>;
			press-threshold-microvolt = <0x61d8d>;
		};
	};

	chosen {
		bootargs = "earlycon=uart8250,mmio32,0xff4c0000 console=ttyFIQ0 root=/dev/mmcblk1p7 rootwait snd_soc_core.prealloc_buffer_size_kbytes=16 coherent_pool=0";
	};

	vcc_1v8: vcc-1v8 {
		compatible = "regulator-fixed";
		regulator-name = "vcc_1v8";
		regulator-always-on;
		regulator-boot-on;
		regulator-min-microvolt = <0x1b7740>;
		regulator-max-microvolt = <0x1b7740>;
		phandle = <0x22>;
	};

	vcc_3v3: vcc-3v3 {
		compatible = "regulator-fixed";
		regulator-name = "vcc_3v3";
		regulator-always-on;
		regulator-boot-on;
		regulator-min-microvolt = <0x325aa0>;
		regulator-max-microvolt = <0x325aa0>;
		phandle = <0x14d>;
	};

	vdd_arm: vdd-arm {
		compatible = "regulator-fixed";
		regulator-name = "vdd_arm";
		regulator-min-microvolt = "", "\f5";
		regulator-max-microvolt = <0xf4240>;
		regulator-init-microvolt = <0xdbba0>;
		regulator-always-on;
		regulator-boot-on;
		phandle = <0x04>;
	};

	gpio-keys {
		compatible = "gpio-keys";
		pinctrl-names = "default";
		pinctrl-0 = <0x57>;

		power-key {
			label = "power";
			gpios = <0x58 0x02 0x01>;
			linux,code = <0x74>;
			debounce-interval = <0x14>;
			wakeup-source;
		};
	};

	gpio_poweroff: gpio-poweroff {
		compatible = "gpio-poweroff";
		pinctrl-names = "default";
		pinctrl-0 = <0x59>;
		gpios = <0x58 0x04 0x00>;
		timeout-ms = <0xbb8>;
		custom,override-pm-power-off;
		phandle = <0x14e>;
	};

	leds {
		compatible = "gpio-leds";
		pinctrl-names = "default";
		pinctrl-0 = <0x5a 0x5b>;

		led_status: led-status {
			label = "status";
			gpios = <0x58 0x03 0x01>;
			linux,default-trigger = "heartbeat";
			default-state = "off";
			phandle = <0x14f>;
		};

		led_eth: led-eth {
			label = "eth";
			gpios = <0x5c 0x02 0x00>;
			linux,default-trigger = "netdev";
			default-state = "off";
			phandle = <0x150>;
		};
	};

	__symbols__ {
		cpu_pvtpll = "/clocks/cpu-pvtpll";
		rkvenc_pvtpll = "/clocks/pvtpll-0";
		npu_pvtpll = "/clocks/pvtpll-1";
		xin24m = "/clocks/oscillator";
		cpu0 = "/cpus/cpu@0";
		cpu0_opp_table = "/cpu0-opp-table";
		csi2_dphy0 = "/csi2-dphy0";
		csi2_dphy1 = "/csi2-dphy1";
		csi2_dphy2 = "/csi2-dphy2";
		display_subsystem = "/display-subsystem";
		route_rgb = "/display-subsystem/route/route-rgb";
		fiq_debugger = "/fiq-debugger";
		optee = "/firmware/optee";
		mipi0_csi2 = "/mipi0-csi2";
		mipi1_csi2 = "/mipi1-csi2";
		mpp_srv = "/mpp-srv";
		mpp_vcodec = "/mpp-vcodec";
		rkcif_dvp = "/rkcif-dvp";
		rkcif_dvp_sditf = "/rkcif-dvp-sditf";
		rkcif_mipi_lvds = "/rkcif-mipi-lvds";
		rkcif_mipi_lvds_sditf = "/rkcif-mipi-lvds-sditf";
		rkcif_mipi_lvds1 = "/rkcif-mipi-lvds1";
		rkcif_mipi_lvds1_sditf = "/rkcif-mipi-lvds1-sditf";
		rkisp_vir0 = "/rkisp-vir0";
		rkisp_vir1 = "/rkisp-vir1";
		rkisp_vir2 = "/rkisp-vir2";
		rkisp_vir3 = "/rkisp-vir3";
		rockchip_suspend = "/rockchip-suspend";
		rockchip_system_monitor = "/rockchip-system-monitor";
		thermal_zones = "/thermal-zones";
		soc_thermal = "/thermal-zones/soc-thermal";
		threshold = "/thermal-zones/soc-thermal/trips/trip-point-0";
		target = "/thermal-zones/soc-thermal/trips/trip-point-1";
		soc_crit = "/thermal-zones/soc-thermal/trips/soc-crit";
		grf = "/syscon@ff000000";
		grf_cru = "/syscon@ff000000/grf-clock-controller";
		reboot_mode = "/syscon@ff000000/reboot-mode";
		rgb = "/syscon@ff000000/rgb";
		rgb_in_vop = "/syscon@ff000000/rgb/ports/port@0/endpoint@0";
		rknpor_powergood = "/syscon@ff000000/rknpor-powergood";
		rtc = "/rtc@ff1c0000";
		gic = "/interrupt-controller@ff1f0000";
		pmu = "/power-management@ff300000";
		i2c0 = "/i2c@ff310000";
		i2c1 = "/i2c@ff320000";
		dsm = "/codec-digital@ff340000";
		pwm0 = "/pwm@ff350000";
		pwm1 = "/pwm@ff350010";
		pwm2 = "/pwm@ff350020";
		pwm3 = "/pwm@ff350030";
		pwm4 = "/pwm@ff360000";
		pwm5 = "/pwm@ff360010";
		pwm6 = "/pwm@ff360020";
		pwm7 = "/pwm@ff360030";
		pmu_mailbox = "/mailbox@ff378000";
		pmuioc = "/syscon@ff388000";
		cru = "/clock-controller@ff3a0000";
		saradc = "/saradc@ff3c0000";
		tsadc = "/tsadc@ff3c8000";
		otp = "/otp@ff3d0000";
		cpu_code = "/otp@ff3d0000/cpu-code@2";
		otp_cpu_version = "/otp@ff3d0000/cpu-version@8";
		otp_id = "/otp@ff3d0000/id@a";
		cpu_leakage = "/otp@ff3d0000/cpu-leakage@1a";
		log_leakage = "/otp@ff3d0000/log-leakage@1b";
		macphy_bgs = "/otp@ff3d0000/macphy-bgs@2d";
		macphy_txlevel = "/otp@ff3d0000/macphy-txlevel@2e";
		u2phy = "/usb2-phy@ff3e0000";
		u2phy_otg = "/usb2-phy@ff3e0000/otg-port";
		csi2_dphy_hw = "/csi2-dphy-hw@ff3e8000";
		dmac = "/dma-controller@ff420000";
		crypto = "/crypto@ff440000";
		rng = "/rng@ff448000";
		i2c2 = "/i2c@ff450000";
		i2c3 = "/i2c@ff460000";
		i2c4 = "/i2c@ff470000";
		acodec = "/acodec@ff480000";
		pwm8 = "/pwm@ff490000";
		pwm9 = "/pwm@ff490010";
		pwm10 = "/pwm@ff490020";
		pwm11 = "/pwm@ff490030";
		uart0 = "/serial@ff4a0000";
		uart1 = "/serial@ff4b0000";
		uart2 = "/serial@ff4c0000";
		uart3 = "/serial@ff4d0000";
		uart4 = "/serial@ff4e0000";
		uart5 = "/serial@ff4f0000";
		spi0 = "/spi@ff500000";
		spi1 = "/spi@ff510000";
		hw_decompress = "/decompress@ff520000";
		ioc = "/syscon@ff538000";
		wdt = "/watchdog@ff5a0000";
		mailbox = "/mailbox@ff5c0000";
		npu = "/npu@ff660000";
		system_sram = "/sram@ff6c0000";
		rkisp_sram = "/sram@ff6c0000/rkisp-sram@0";
		hpmcu_sram = "/sram@ff6c0000/hpmcu-sram@3e000";
		rga2 = "/rga@ff980000";
		vop = "/vop@ff990000";
		vop_out = "/vop@ff990000/port";
		vop_out_rgb = "/vop@ff990000/port/endpoint@0";
		sdio = "/mmc@ff9a0000";
		rkisp = "/rkisp@ffa00000";
		rkcif = "/rkcif@ffa10000";
		mipi0_csi2_hw = "/mipi-csi2-hw@ffa20000";
		mipi1_csi2_hw = "/mipi-csi2-hw@ffa30000";
		rkvenc = "/rkvenc@ffa50000";
		rkvenc_pp = "/rkvenc-pp@ffa60000";
		rkdvbm = "/rkdvbm@ffa70000";
		gmac = "/ethernet@ffa80000";
		mdio = "/ethernet@ffa80000/mdio";
		rmii_phy = "/ethernet@ffa80000/mdio/ethernet-phy@2";
		stmmac_axi_setup = "/ethernet@ffa80000/stmmac-axi-config";
		mtl_rx_setup = "/ethernet@ffa80000/rx-queues-config";
		mtl_tx_setup = "/ethernet@ffa80000/tx-queues-config";
		emmc = "/mmc@ffa90000";
		sdmmc = "/mmc@ffaa0000";
		sfc = "/spi@ffac0000";
		rve = "/rve@ffad0000";
		i2s0_8ch = "/i2s@ffae0000";
		usbdrd = "/usbdrd";
		usbdrd_dwc3 = "/usbdrd/usb@ffb00000";
		pinctrl = "/pinctrl";
		gpio0 = "/pinctrl/gpio@ff380000";
		gpio1 = "/pinctrl/gpio@ff530000";
		gpio2 = "/pinctrl/gpio@ff540000";
		gpio3 = "/pinctrl/gpio@ff550000";
		gpio4 = "/pinctrl/gpio@ff560000";
		pcfg_pull_up = "/pinctrl/pcfg-pull-up";
		pcfg_pull_down = "/pinctrl/pcfg-pull-down";
		pcfg_pull_none = "/pinctrl/pcfg-pull-none";
		pcfg_pull_none_drv_level_0 = "/pinctrl/pcfg-pull-none-drv-level-0";
		pcfg_pull_none_drv_level_1 = "/pinctrl/pcfg-pull-none-drv-level-1";
		pcfg_pull_none_drv_level_2 = "/pinctrl/pcfg-pull-none-drv-level-2";
		pcfg_pull_none_drv_level_3 = "/pinctrl/pcfg-pull-none-drv-level-3";
		pcfg_pull_none_drv_level_4 = "/pinctrl/pcfg-pull-none-drv-level-4";
		pcfg_pull_none_drv_level_5 = "/pinctrl/pcfg-pull-none-drv-level-5";
		pcfg_pull_none_drv_level_6 = "/pinctrl/pcfg-pull-none-drv-level-6";
		pcfg_pull_none_drv_level_7 = "/pinctrl/pcfg-pull-none-drv-level-7";
		pcfg_pull_none_drv_level_8 = "/pinctrl/pcfg-pull-none-drv-level-8";
		pcfg_pull_none_drv_level_9 = "/pinctrl/pcfg-pull-none-drv-level-9";
		pcfg_pull_none_drv_level_10 = "/pinctrl/pcfg-pull-none-drv-level-10";
		pcfg_pull_none_drv_level_11 = "/pinctrl/pcfg-pull-none-drv-level-11";
		pcfg_pull_none_drv_level_12 = "/pinctrl/pcfg-pull-none-drv-level-12";
		pcfg_pull_none_drv_level_13 = "/pinctrl/pcfg-pull-none-drv-level-13";
		pcfg_pull_none_drv_level_14 = "/pinctrl/pcfg-pull-none-drv-level-14";
		pcfg_pull_none_drv_level_15 = "/pinctrl/pcfg-pull-none-drv-level-15";
		pcfg_pull_up_drv_level_0 = "/pinctrl/pcfg-pull-up-drv-level-0";
		pcfg_pull_up_drv_level_1 = "/pinctrl/pcfg-pull-up-drv-level-1";
		pcfg_pull_up_drv_level_2 = "/pinctrl/pcfg-pull-up-drv-level-2";
		pcfg_pull_up_drv_level_3 = "/pinctrl/pcfg-pull-up-drv-level-3";
		pcfg_pull_up_drv_level_4 = "/pinctrl/pcfg-pull-up-drv-level-4";
		pcfg_pull_up_drv_level_5 = "/pinctrl/pcfg-pull-up-drv-level-5";
		pcfg_pull_up_drv_level_6 = "/pinctrl/pcfg-pull-up-drv-level-6";
		pcfg_pull_up_drv_level_7 = "/pinctrl/pcfg-pull-up-drv-level-7";
		pcfg_pull_up_drv_level_8 = "/pinctrl/pcfg-pull-up-drv-level-8";
		pcfg_pull_up_drv_level_9 = "/pinctrl/pcfg-pull-up-drv-level-9";
		pcfg_pull_up_drv_level_10 = "/pinctrl/pcfg-pull-up-drv-level-10";
		pcfg_pull_up_drv_level_11 = "/pinctrl/pcfg-pull-up-drv-level-11";
		pcfg_pull_up_drv_level_12 = "/pinctrl/pcfg-pull-up-drv-level-12";
		pcfg_pull_up_drv_level_13 = "/pinctrl/pcfg-pull-up-drv-level-13";
		pcfg_pull_up_drv_level_14 = "/pinctrl/pcfg-pull-up-drv-level-14";
		pcfg_pull_up_drv_level_15 = "/pinctrl/pcfg-pull-up-drv-level-15";
		pcfg_pull_down_drv_level_0 = "/pinctrl/pcfg-pull-down-drv-level-0";
		pcfg_pull_down_drv_level_1 = "/pinctrl/pcfg-pull-down-drv-level-1";
		pcfg_pull_down_drv_level_2 = "/pinctrl/pcfg-pull-down-drv-level-2";
		pcfg_pull_down_drv_level_3 = "/pinctrl/pcfg-pull-down-drv-level-3";
		pcfg_pull_down_drv_level_4 = "/pinctrl/pcfg-pull-down-drv-level-4";
		pcfg_pull_down_drv_level_5 = "/pinctrl/pcfg-pull-down-drv-level-5";
		pcfg_pull_down_drv_level_6 = "/pinctrl/pcfg-pull-down-drv-level-6";
		pcfg_pull_down_drv_level_7 = "/pinctrl/pcfg-pull-down-drv-level-7";
		pcfg_pull_down_drv_level_8 = "/pinctrl/pcfg-pull-down-drv-level-8";
		pcfg_pull_down_drv_level_9 = "/pinctrl/pcfg-pull-down-drv-level-9";
		pcfg_pull_down_drv_level_10 = "/pinctrl/pcfg-pull-down-drv-level-10";
		pcfg_pull_down_drv_level_11 = "/pinctrl/pcfg-pull-down-drv-level-11";
		pcfg_pull_down_drv_level_12 = "/pinctrl/pcfg-pull-down-drv-level-12";
		pcfg_pull_down_drv_level_13 = "/pinctrl/pcfg-pull-down-drv-level-13";
		pcfg_pull_down_drv_level_14 = "/pinctrl/pcfg-pull-down-drv-level-14";
		pcfg_pull_down_drv_level_15 = "/pinctrl/pcfg-pull-down-drv-level-15";
		pcfg_pull_up_smt = "/pinctrl/pcfg-pull-up-smt";
		pcfg_pull_down_smt = "/pinctrl/pcfg-pull-down-smt";
		pcfg_pull_none_smt = "/pinctrl/pcfg-pull-none-smt";
		pcfg_pull_none_drv_level_0_smt = "/pinctrl/pcfg-pull-none-drv-level-0-smt";
		pcfg_output_high = "/pinctrl/pcfg-output-high";
		pcfg_output_high_pull_up = "/pinctrl/pcfg-output-high-pull-up";
		pcfg_output_high_pull_down = "/pinctrl/pcfg-output-high-pull-down";
		pcfg_output_high_pull_none = "/pinctrl/pcfg-output-high-pull-none";
		pcfg_output_low = "/pinctrl/pcfg-output-low";
		pcfg_output_low_pull_up = "/pinctrl/pcfg-output-low-pull-up";
		pcfg_output_low_pull_down = "/pinctrl/pcfg-output-low-pull-down";
		pcfg_output_low_pull_none = "/pinctrl/pcfg-output-low-pull-none";
		adc_pins = "/pinctrl/adc/adc-pins";
		avs_pins = "/pinctrl/avs/avs-pins";
		clk_32k = "/pinctrl/clk/clk-32k";
		clk_refout = "/pinctrl/clk/clk-refout";
		dsmaudio_pins = "/pinctrl/dsmaudio/dsmaudio-pins";
		emmc_bus8 = "/pinctrl/emmc/emmc-bus8";
		emmc_clk = "/pinctrl/emmc/emmc-clk";
		emmc_cmd = "/pinctrl/emmc/emmc-cmd";
		flash_pins = "/pinctrl/flash/flash-pins";
		fspi_pins = "/pinctrl/fspi/fspi-pins";
		fspi_cs0 = "/pinctrl/fspi/fspi-cs0";
		hpmcum0_pins = "/pinctrl/hpmcu/hpmcum0-pins";
		hpmcum1_pins = "/pinctrl/hpmcu/hpmcum1-pins";
		i2c0m0_xfer = "/pinctrl/i2c0/i2c0m0-xfer";
		i2c0m1_xfer = "/pinctrl/i2c0/i2c0m1-xfer";
		i2c0m2_xfer = "/pinctrl/i2c0/i2c0m2-xfer";
		i2c1m0_xfer = "/pinctrl/i2c1/i2c1m0-xfer";
		i2c1m1_xfer = "/pinctrl/i2c1/i2c1m1-xfer";
		i2c2m0_xfer = "/pinctrl/i2c2/i2c2m0-xfer";
		i2c2m1_xfer = "/pinctrl/i2c2/i2c2m1-xfer";
		i2c3m0_xfer = "/pinctrl/i2c3/i2c3m0-xfer";
		i2c3m1_xfer = "/pinctrl/i2c3/i2c3m1-xfer";
		i2c3m2_xfer = "/pinctrl/i2c3/i2c3m2-xfer";
		i2c4m0_xfer = "/pinctrl/i2c4/i2c4m0-xfer";
		i2c4m1_xfer = "/pinctrl/i2c4/i2c4m1-xfer";
		i2c4m2_xfer = "/pinctrl/i2c4/i2c4m2-xfer";
		i2s0_pins = "/pinctrl/i2s0/i2s0-pins";
		lcd_pins = "/pinctrl/lcd/lcd-pins";
		bt1120_pins = "/pinctrl/lcd/bt1120-pins";
		bt656_pins = "/pinctrl/lcd/bt656-pins";
		rgb3x8_pins = "/pinctrl/lcd/rgb3x8-pins";
		rgb565_pins = "/pinctrl/lcd/rgb565-pins";
		lpmcum0_pins = "/pinctrl/lpmcu/lpmcum0-pins";
		lpmcum1_pins = "/pinctrl/lpmcu/lpmcum1-pins";
		mipi_pins = "/pinctrl/mipi/mipi-pins";
		mipi_refclk_out0 = "/pinctrl/mipi/mipi-refclk-out0";
		mipi_refclk_out1 = "/pinctrl/mipi/mipi-refclk-out1";
		pmicm0_pins = "/pinctrl/pmic/pmicm0-pins";
		pmicm1_pins = "/pinctrl/pmic/pmicm1-pins";
		pmu_pins = "/pinctrl/pmu/pmu-pins";
		prelight_pins = "/pinctrl/prelight/prelight-pins";
		pwm0m0_pins = "/pinctrl/pwm0/pwm0m0-pins";
		pwm0m1_pins = "/pinctrl/pwm0/pwm0m1-pins";
		pwm1m0_pins = "/pinctrl/pwm1/pwm1m0-pins";
		pwm1m1_pins = "/pinctrl/pwm1/pwm1m1-pins";
		pwm1m2_pins = "/pinctrl/pwm1/pwm1m2-pins";
		pwm2m0_pins = "/pinctrl/pwm2/pwm2m0-pins";
		pwm2m1_pins = "/pinctrl/pwm2/pwm2m1-pins";
		pwm2m2_pins = "/pinctrl/pwm2/pwm2m2-pins";
		pwm3m0_pins = "/pinctrl/pwm3/pwm3m0-pins";
		pwm3m1_pins = "/pinctrl/pwm3/pwm3m1-pins";
		pwm3m2_pins = "/pinctrl/pwm3/pwm3m2-pins";
		pwm4m0_pins = "/pinctrl/pwm4/pwm4m0-pins";
		pwm4m1_pins = "/pinctrl/pwm4/pwm4m1-pins";
		pwm4m2_pins = "/pinctrl/pwm4/pwm4m2-pins";
		pwm5m0_pins = "/pinctrl/pwm5/pwm5m0-pins";
		pwm5m1_pins = "/pinctrl/pwm5/pwm5m1-pins";
		pwm5m2_pins = "/pinctrl/pwm5/pwm5m2-pins";
		pwm6m0_pins = "/pinctrl/pwm6/pwm6m0-pins";
		pwm6m1_pins = "/pinctrl/pwm6/pwm6m1-pins";
		pwm6m2_pins = "/pinctrl/pwm6/pwm6m2-pins";
		pwm7m0_pins = "/pinctrl/pwm7/pwm7m0-pins";
		pwm7m1_pins = "/pinctrl/pwm7/pwm7m1-pins";
		pwm7m2_pins = "/pinctrl/pwm7/pwm7m2-pins";
		pwm8m0_pins = "/pinctrl/pwm8/pwm8m0-pins";
		pwm8m1_pins = "/pinctrl/pwm8/pwm8m1-pins";
		pwm9m0_pins = "/pinctrl/pwm9/pwm9m0-pins";
		pwm9m1_pins = "/pinctrl/pwm9/pwm9m1-pins";
		pwm10m0_pins = "/pinctrl/pwm10/pwm10m0-pins";
		pwm10m1_pins = "/pinctrl/pwm10/pwm10m1-pins";
		pwm10m2_pins = "/pinctrl/pwm10/pwm10m2-pins";
		pwm11m0_pins = "/pinctrl/pwm11/pwm11m0-pins";
		pwm11m1_pins = "/pinctrl/pwm11/pwm11m1-pins";
		pwm11m2_pins = "/pinctrl/pwm11/pwm11m2-pins";
		rtc_pins = "/pinctrl/rtc/rtc-pins";
		sdmmc0_bus4 = "/pinctrl/sdmmc0/sdmmc0-bus4";
		sdmmc0_clk = "/pinctrl/sdmmc0/sdmmc0-clk";
		sdmmc0_cmd = "/pinctrl/sdmmc0/sdmmc0-cmd";
		sdmmc0_det = "/pinctrl/sdmmc0/sdmmc0-det";
		sdmmc0_idle_pins = "/pinctrl/sdmmc0/sdmmc0-idle-pins";
		sdmmc1m0_bus1 = "/pinctrl/sdmmc1/sdmmc1m0-bus1";
		sdmmc1m0_bus4 = "/pinctrl/sdmmc1/sdmmc1m0-bus4";
		sdmmc1m0_clk = "/pinctrl/sdmmc1/sdmmc1m0-clk";
		sdmmc1m0_cmd = "/pinctrl/sdmmc1/sdmmc1m0-cmd";
		sdmmc1m0_idle_pins = "/pinctrl/sdmmc1/sdmmc1m0-idle-pins";
		sdmmc1m1_bus4 = "/pinctrl/sdmmc1/sdmmc1m1-bus4";
		sdmmc1m1_clk = "/pinctrl/sdmmc1/sdmmc1m1-clk";
		sdmmc1m1_cmd = "/pinctrl/sdmmc1/sdmmc1m1-cmd";
		sdmmc1m1_idle_pins = "/pinctrl/sdmmc1/sdmmc1m1-idle-pins";
		spi0m0_pins = "/pinctrl/spi0/spi0m0-pins";
		spi0m0_cs0 = "/pinctrl/spi0/spi0m0-cs0";
		spi0m0_cs1 = "/pinctrl/spi0/spi0m0-cs1";
		spi1m0_pins = "/pinctrl/spi1/spi1m0-pins";
		spi1m0_cs0 = "/pinctrl/spi1/spi1m0-cs0";
		spi1m0_cs1 = "/pinctrl/spi1/spi1m0-cs1";
		uart0m0_xfer = "/pinctrl/uart0/uart0m0-xfer";
		uart0m1_xfer = "/pinctrl/uart0/uart0m1-xfer";
		uart0m1_ctsn = "/pinctrl/uart0/uart0m1-ctsn";
		uart0m1_rtsn = "/pinctrl/uart0/uart0m1-rtsn";
		uart0m2_xfer = "/pinctrl/uart0/uart0m2-xfer";
		uart1m0_xfer = "/pinctrl/uart1/uart1m0-xfer";
		uart1m0_ctsn = "/pinctrl/uart1/uart1m0-ctsn";
		uart1m0_rtsn = "/pinctrl/uart1/uart1m0-rtsn";
		uart1m1_xfer = "/pinctrl/uart1/uart1m1-xfer";
		uart1m1_ctsn = "/pinctrl/uart1/uart1m1-ctsn";
		uart1m1_rtsn = "/pinctrl/uart1/uart1m1-rtsn";
		uart1m2_xfer = "/pinctrl/uart1/uart1m2-xfer";
		uart2m0_xfer = "/pinctrl/uart2/uart2m0-xfer";
		uart2m1_xfer = "/pinctrl/uart2/uart2m1-xfer";
		uart3m0_xfer = "/pinctrl/uart3/uart3m0-xfer";
		uart3m1_xfer = "/pinctrl/uart3/uart3m1-xfer";
		uart4m0_xfer = "/pinctrl/uart4/uart4m0-xfer";
		uart4m1_xfer = "/pinctrl/uart4/uart4m1-xfer";
		uart4m1_ctsn = "/pinctrl/uart4/uart4m1-ctsn";
		uart4m1_rtsn = "/pinctrl/uart4/uart4m1-rtsn";
		uart5m0_xfer = "/pinctrl/uart5/uart5m0-xfer";
		uart5m0_ctsn = "/pinctrl/uart5/uart5m0-ctsn";
		uart5m0_rtsn = "/pinctrl/uart5/uart5m0-rtsn";
		uart5m1_xfer = "/pinctrl/uart5/uart5m1-xfer";
		uart5m1_ctsn = "/pinctrl/uart5/uart5m1-ctsn";
		uart5m1_rtsn = "/pinctrl/uart5/uart5m1-rtsn";
		uart5m2_xfer = "/pinctrl/uart5/uart5m2-xfer";
		uart5m2_ctsn = "/pinctrl/uart5/uart5m2-ctsn";
		uart5m2_rtsn = "/pinctrl/uart5/uart5m2-rtsn";
		vicapm0_pins = "/pinctrl/vicap/vicapm0-pins";
		vicapm1_pins = "/pinctrl/vicap/vicapm1-pins";
		vicap_d10 = "/pinctrl/vicap/vicap-d10";
		vicap_d11 = "/pinctrl/vicap/vicap-d11";
		vicap_d12 = "/pinctrl/vicap/vicap-d12";
		vicap_d13 = "/pinctrl/vicap/vicap-d13";
		vicap_d14 = "/pinctrl/vicap/vicap-d14";
		vicap_d15 = "/pinctrl/vicap/vicap-d15";
		vicap_clkout_m0 = "/pinctrl/vicap/vicap-clkout-m0";
		vicap_clkout_m1 = "/pinctrl/vicap/vicap-clkout-m1";
		pb_int_n_pin = "/pinctrl/board-gpio/pb-int-n-pin";
		pwr_kill_pin = "/pinctrl/board-gpio/pwr-kill-pin";
		led_status_pin = "/pinctrl/board-gpio/led-status-pin";
		led_eth_pin = "/pinctrl/board-gpio/led-eth-pin";
		rockchip_amp = "/rockchip-amp";
		vcc_1v8 = "/vcc-1v8";
		vcc_3v3 = "/vcc-3v3";
		vdd_arm = "/vdd-arm";
		gpio_poweroff = "/gpio-poweroff";
		led_status = "/leds/led-status";
		led_eth = "/leds/led-eth";
	};
};
